VERSION "f33"

NS_ :

BS_:

BU_: C70 VC BMS CHG DASH PBX MCAN OA

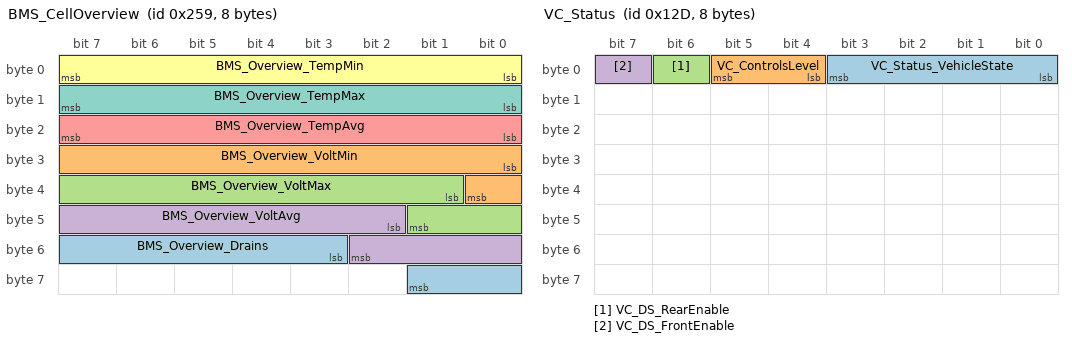
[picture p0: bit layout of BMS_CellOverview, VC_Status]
BO_ 601 BMS_CellOverview: 8 BMS
 SG_ BMS_Overview_Drains : 51|7@1+ (1,0) [0|76] "" Vector__XXX
 SG_ BMS_Overview_VoltMin : 24|9@1+ (0.01,0) [0|5.12] "V"  DASH
 SG_ BMS_Overview_VoltMax : 33|9@1+ (0.01,0) [0|5.12] "V"  DASH
 SG_ BMS_Overview_VoltAvg : 42|9@1+ (0.01,0) [0|5.12] "V" Vector__XXX
 SG_ BMS_Overview_TempAvg : 16|8@1- (1,0) [-128|127] "C" Vector__XXX
 SG_ BMS_Overview_TempMin : 0|8@1- (1,0) [-128|127] "C" Vector__XXX
 SG_ BMS_Overview_TempMax : 8|8@1- (1,0) [-128|127] "C" Vector__XXX

BO_ 301 VC_Status: 8 VC
 SG_ VC_Status_VehicleState : 0|4@1+ (1,0) [0|15] ""  Vector__XXX
 SG_ VC_ControlsLevel : 4|2@1+ (1,0) [0|0] "" Vector__XXX
 SG_ VC_DS_RearEnable : 6|1@1+ (1,0) [0|0] "" Vector__XXX
 SG_ VC_DS_FrontEnable : 7|1@1+ (1,0) [0|0] "" Vector__XXX

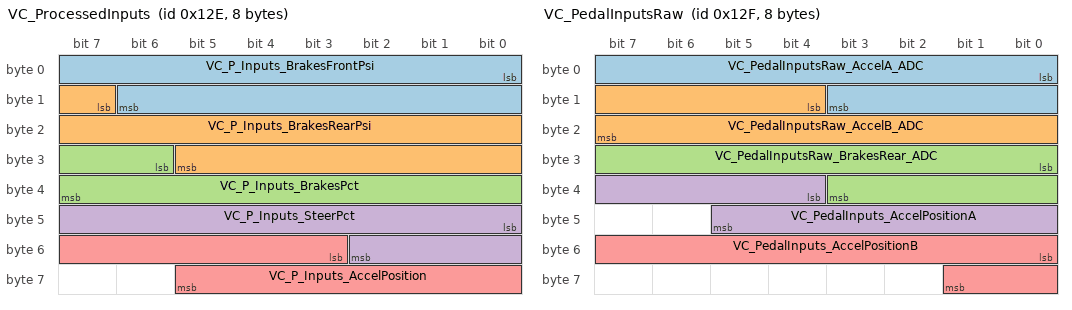
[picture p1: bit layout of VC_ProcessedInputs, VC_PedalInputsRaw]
BO_ 302 VC_ProcessedInputs: 8 VC
 SG_ VC_P_Inputs_BrakesFrontPsi : 0|15@1+ (0.1,0) [0|3000] "psi" Vector__XXX
 SG_ VC_P_Inputs_BrakesRearPsi : 15|15@1+ (0.1,0) [0|3000] "psi" Vector__XXX
 SG_ VC_P_Inputs_BrakesPct : 30|10@1+ (0.1,0) [0|100] "%" Vector__XXX
 SG_ VC_P_Inputs_SteerPct : 40|11@1- (0.1,0) [-100|100] "%" Vector__XXX
 SG_ VC_P_Inputs_AccelPosition : 51|11@1- (0.1,0) [-100|100] "%" Vector__XXX

BO_ 303 VC_PedalInputsRaw: 8 VC
 SG_ VC_PedalInputsRaw_AccelA_ADC : 0|12@1+ (1,0) [0|4095] "" Vector__XXX
 SG_ VC_PedalInputsRaw_AccelB_ADC : 12|12@1+ (1,0) [0|4095] "" Vector__XXX
 SG_ VC_PedalInputsRaw_BrakesRear_ADC : 24|12@1+ (1,0) [0|4095] "" Vector__XXX
 SG_ VC_PedalInputs_AccelPositionA : 36|10@1+ (0.1,0) [0|100] "%" Vector__XXX
 SG_ VC_PedalInputs_AccelPositionB : 48|10@1+ (0.1,0) [0|100] "%" Vector__XXX

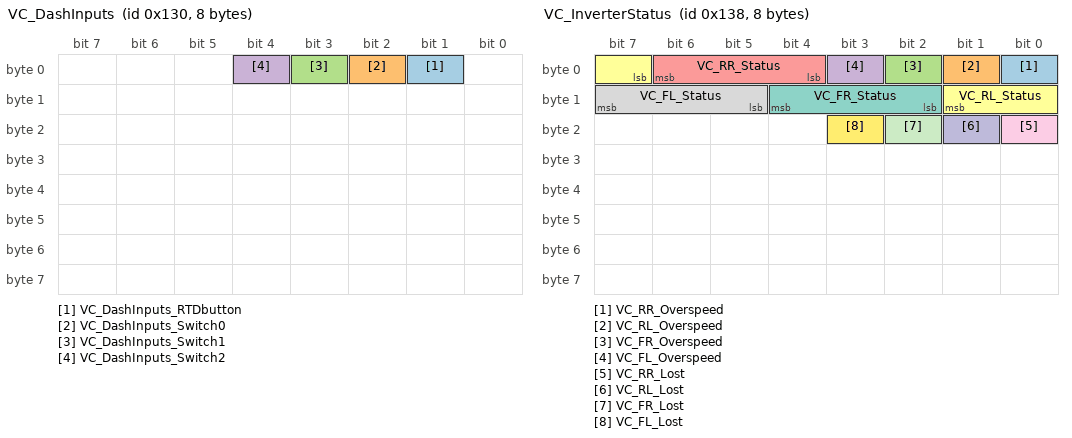
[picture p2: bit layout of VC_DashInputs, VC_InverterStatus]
BO_ 304 VC_DashInputs: 8 VC
 SG_ VC_DashInputs_RTDbutton : 1|1@1+ (1,0) [0|1] "" Vector__XXX
 SG_ VC_DashInputs_Switch0 : 2|1@1+ (1,0) [0|1] "" Vector__XXX
 SG_ VC_DashInputs_Switch1 : 3|1@1+ (1,0) [0|1] "" Vector__XXX
 SG_ VC_DashInputs_Switch2 : 4|1@1+ (1,0) [0|1] "" Vector__XXX

BO_ 311 VC_FaultVector: 8 VC
 SG_ VC_PBX_SHUTDOWN_CONTROL : 0|1@1+ (1,0) [0|1] ""  Vector__XXX
 SG_ VC_ShutdownStatus_BMS_fault : 1|1@1+ (1,0) [0|1] "" Vector__XXX
 SG_ VC_FaultVector_ACCEL_A_IRRA : 2|1@1+ (1,0) [0|1] "" Vector__XXX
 SG_ VC_FaultVector_ACCEL_B_IRRA : 3|1@1+ (1,0) [0|1] "" Vector__XXX
 SG_ VC_FaultVector_APPS_DISAG : 4|1@1+ (1,0) [0|1] "" Vector__XXX
 SG_ VC_FaultVector_APPS_DOUBLE_PEDAL : 5|1@1+ (1,0) [0|1] "" Vector__XXX
 SG_ VC_FaultVector_FSSDB_LOST : 6|1@1+ (1,0) [0|1] "" Vector__XXX
 SG_ VC_FaultVector_FBPS_IRRA : 7|1@1+ (1,0) [0|1] "" Vector__XXX
 SG_ VC_FaultVector_RBPS_IRRA : 8|1@1+ (1,0) [0|1] "" Vector__XXX
 SG_ VC_FaultVector_STEER_IRRA : 9|1@1+ (1,0) [0|1] ""  Vector__XXX
 SG_ VC_FaultVector_RSSDB_LOST : 10|1@1+ (1,0) [0|1] ""  Vector__XXX
 SG_ VC_FaultVector_RR_ERROR : 11|1@1+ (1,0) [0|1] ""  Vector__XXX
 SG_ VC_FaultVector_RL_ERROR : 12|1@1+ (1,0) [0|1] ""  Vector__XXX
 SG_ VC_FaultVector_FR_ERROR : 13|1@1+ (1,0) [0|1] ""  Vector__XXX
 SG_ VC_FaultVector_FL_ERROR : 14|1@1+ (1,0) [0|1] ""  Vector__XXX
 SG_ VC_FaultVector_PC_TIMEOUT : 15|1@1+ (1,0) [0|1] "" Vector__XXX
 SG_ VC_FaultVector_SOFT_DP : 16|1@1+ (1,0) [0|1] "" Vector__XXX
 SG_ VC_FaultVector_VN_NO_LOCK : 17|1@1+ (1,0) [0|1] "" Vector__XXX
 SG_ VC_FaultVector_VN_IRR : 18|1@1+ (1,0) [0|1] "" Vector__XXX
 SG_ VC_FaultVector_RUNAWAY : 19|1@1+ (1,0) [0|1] "" Vector__XXX

BO_ 312 VC_InverterStatus: 8 VC
 SG_ VC_RR_Overspeed : 0|1@1+ (1,0) [0|1] "" Vector__XXX
 SG_ VC_RL_Overspeed : 1|1@1+ (1,0) [0|1] "" Vector__XXX
 SG_ VC_FR_Overspeed : 2|1@1+ (1,0) [0|1] "" Vector__XXX
 SG_ VC_FL_Overspeed : 3|1@1+ (1,0) [0|1] "" Vector__XXX
 SG_ VC_RR_Status : 4|3@1+ (1,0) [0|7] "" Vector__XXX
 SG_ VC_RL_Status : 7|3@1+ (1,0) [0|7] "" Vector__XXX
 SG_ VC_FR_Status : 10|3@1+ (1,0) [0|7] "" Vector__XXX
 SG_ VC_FL_Status : 13|3@1+ (1,0) [0|7] "" Vector__XXX
 SG_ VC_RR_Lost : 16|1@1+ (1,0) [0|1] "" Vector__XXX
 SG_ VC_RL_Lost : 17|1@1+ (1,0) [0|1] "" Vector__XXX
 SG_ VC_FR_Lost : 18|1@1+ (1,0) [0|1] "" Vector__XXX
 SG_ VC_FL_Lost : 19|1@1+ (1,0) [0|1] "" Vector__XXX

BO_ 315 VC_HardFaultIndicator: 8 VC
 SG_ VC_HardFaultIndicator : 0|4@1+ (1,0) [0|15] ""  DASH

BO_ 316 VC_RTDSRequest: 8 VC
 SG_ VC_RequestRTDS : 0|1@1+ (1,0) [0|1] "" Vector__XXX

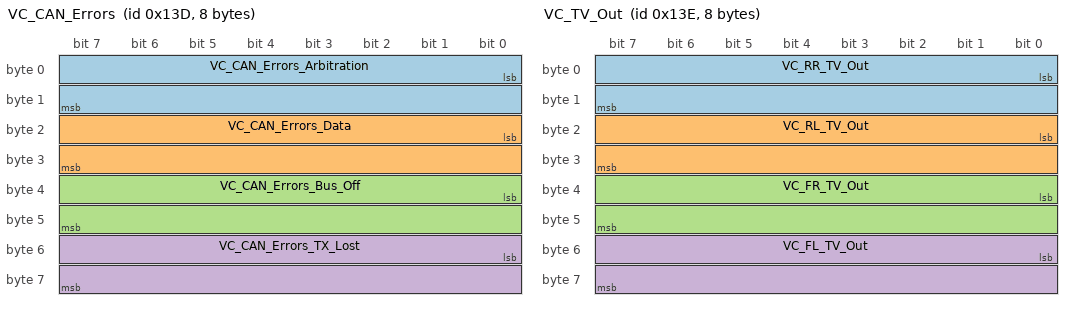
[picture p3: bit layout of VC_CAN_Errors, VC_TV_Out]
BO_ 317 VC_CAN_Errors: 8 VC
 SG_ VC_CAN_Errors_Arbitration : 0|16@1+ (1,0) [0|0] "" Vector__XXX
 SG_ VC_CAN_Errors_Data : 16|16@1+ (1,0) [0|0] "" Vector__XXX
 SG_ VC_CAN_Errors_Bus_Off : 32|16@1+ (1,0) [0|0] "" Vector__XXX
 SG_ VC_CAN_Errors_TX_Lost : 48|16@1+ (1,0) [0|0] "" Vector__XXX

BO_ 318 VC_TV_Out: 8 VC
 SG_ VC_RR_TV_Out: 0|16@1+ (0.1,0) [0|0] "% Mn" Vector__XXX
 SG_ VC_RL_TV_Out: 16|16@1+ (0.1,0) [0|0] "% Mn" Vector__XXX
 SG_ VC_FR_TV_Out: 32|16@1+ (0.1,0) [0|0] "% Mn" Vector__XXX
 SG_ VC_FL_TV_Out: 48|16@1+ (0.1,0) [0|0] "% Mn" Vector__XXX

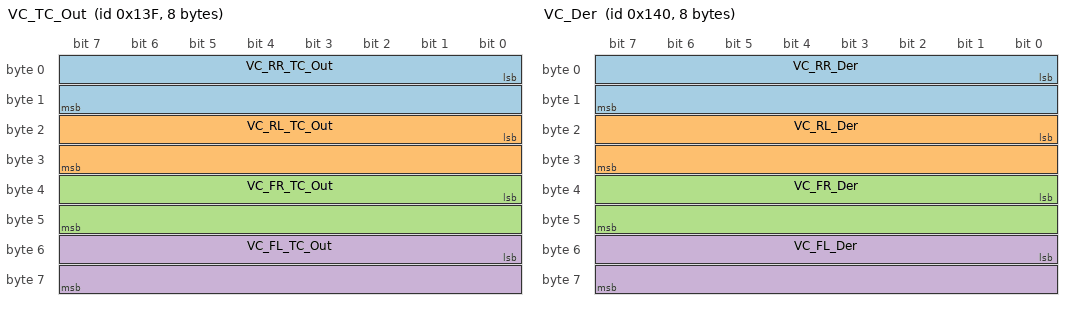
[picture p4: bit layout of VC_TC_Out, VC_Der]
BO_ 319 VC_TC_Out: 8 VC
 SG_ VC_RR_TC_Out: 0|16@1+ (0.1,0) [0|0] "% Mn" Vector__XXX
 SG_ VC_RL_TC_Out: 16|16@1+ (0.1,0) [0|0] "% Mn" Vector__XXX
 SG_ VC_FR_TC_Out: 32|16@1+ (0.1,0) [0|0] "% Mn" Vector__XXX
 SG_ VC_FL_TC_Out: 48|16@1+ (0.1,0) [0|0] "% Mn" Vector__XXX

BO_ 320 VC_Der: 8 VC
 SG_ VC_RR_Der: 0|16@1+ (0.1,0) [0|0] "rpm" Vector__XXX
 SG_ VC_RL_Der: 16|16@1+ (0.1,0) [0|0] "rpm" Vector__XXX
 SG_ VC_FR_Der: 32|16@1+ (0.1,0) [0|0] "rpm" Vector__XXX
 SG_ VC_FL_Der: 48|16@1+ (0.1,0) [0|0] "rpm" Vector__XXX

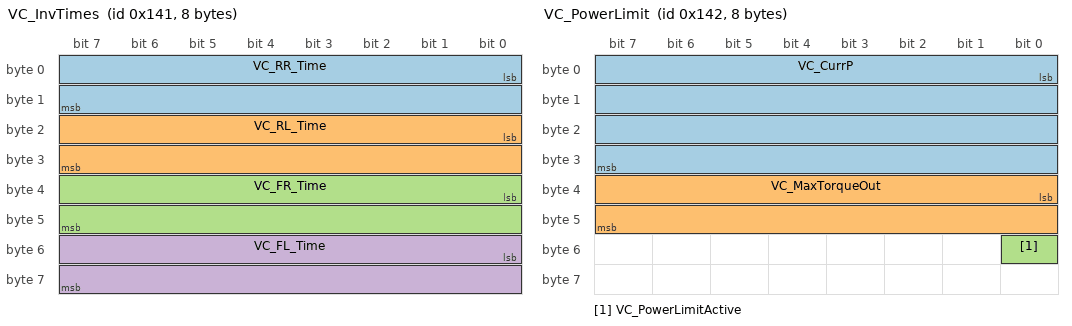
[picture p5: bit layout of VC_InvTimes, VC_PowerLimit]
BO_ 321 VC_InvTimes: 8 VC
 SG_ VC_RR_Time : 0|16@1+ (1,0) [0|65535] "" Vector__XXX
 SG_ VC_RL_Time : 16|16@1+ (1,0) [0|65535] "" Vector__XXX
 SG_ VC_FR_Time : 32|16@1+ (1,0) [0|65535] "" Vector__XXX
 SG_ VC_FL_Time : 48|16@1+ (1,0) [0|65535] "" Vector__XXX

BO_ 322 VC_PowerLimit: 8 VC
 SG_ VC_CurrP : 0|32@1+ (0.01,0) [0|0] "W" Vector__XXX
 SG_ VC_MaxTorqueOut : 32|16@1+ (0.1,0) [0|0] "%Mn" Vector__XXX
 SG_ VC_PowerLimitActive : 48|1@1+ (1,0) [0|1] "" Vector__XXX

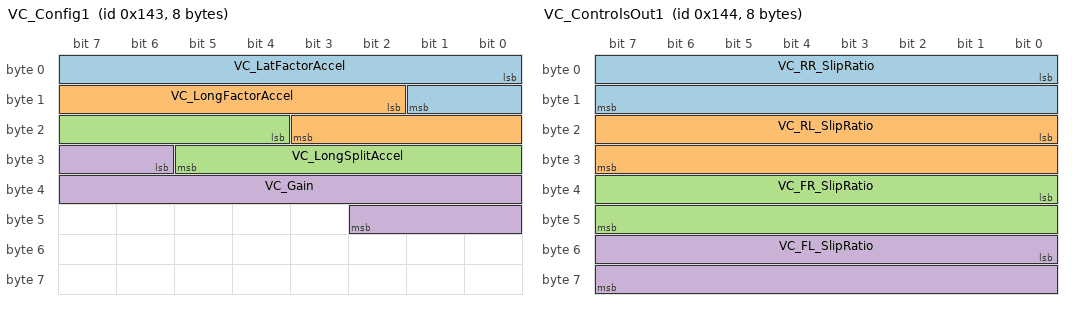
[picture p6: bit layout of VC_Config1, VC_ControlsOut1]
BO_ 323 VC_Config1: 8 VC
 SG_ VC_LatFactorAccel : 0|10@1+ (0.01,0) [0|0] "" Vector__XXX
 SG_ VC_LongFactorAccel : 10|10@1+ (0.01,0) [0|0] "" Vector__XXX
 SG_ VC_LongSplitAccel : 20|10@1+ (0.01,0) [0|0] "" Vector__XXX
 SG_ VC_Gain : 30|13@1+ (0.01,0) [0|0] "" Vector__XXX

BO_ 324 VC_ControlsOut1: 8 VC
 SG_ VC_RR_SlipRatio : 0|16@1+ (0.001,0) [0|0] "" Vector__XXX
 SG_ VC_RL_SlipRatio : 16|16@1+ (0.001,0) [0|0] "" Vector__XXX
 SG_ VC_FR_SlipRatio : 32|16@1+ (0.001,0) [0|0] "" Vector__XXX
 SG_ VC_FL_SlipRatio : 48|16@1+ (0.001,0) [0|0] "" Vector__XXX

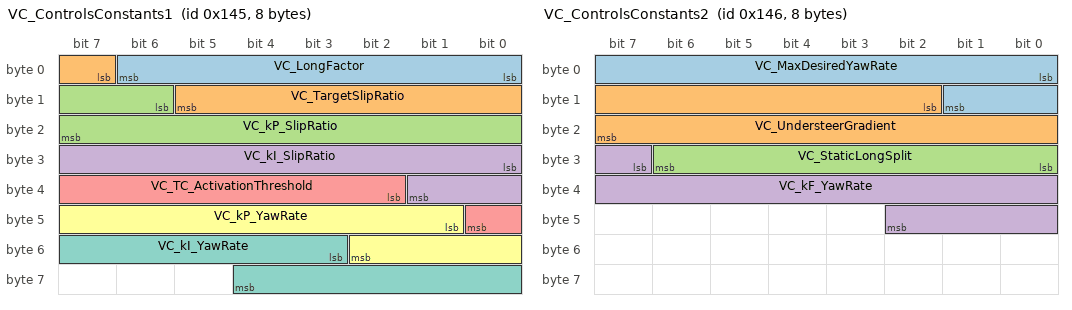
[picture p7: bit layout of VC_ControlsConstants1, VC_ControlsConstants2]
BO_ 325 VC_ControlsConstants1 : 8 VC
 SG_ VC_LongFactor : 0|7@1+ (0.01,0) [0|0] "" Vector__XXX
 SG_ VC_TargetSlipRatio : 7|7@1+ (0.01,0) [0|0] "" Vector__XXX
 SG_ VC_kP_SlipRatio : 14|10@1+ (0.01,0) [0|0] "" Vector__XXX
 SG_ VC_kI_SlipRatio : 24|10@1+ (0.01,0) [0|0] "" Vector__XXX
 SG_ VC_TC_ActivationThreshold : 34|7@1+ (0.01,0) [0|0] "" Vector__XXX
 SG_ VC_kP_YawRate : 41|10@1+ (0.01,0) [0|0] "" Vector__XXX
 SG_ VC_kI_YawRate : 51|10@1+ (0.01,0) [0|0] "" Vector__XXX

BO_ 326 VC_ControlsConstants2 : 8 VC
 SG_ VC_MaxDesiredYawRate : 0|10@1+ (0.01,0) [0|0] "" Vector__XXX
 SG_ VC_UndersteerGradient : 10|14@1+ (0.00001,0) [0|0] "" Vector__XXX
 SG_ VC_StaticLongSplit : 24|7@1+ (0.01,0) [0|0] "" Vector__XXX
 SG_ VC_kF_YawRate : 31|12@1+ (0.01, 0) [0|0] "" Vector__XXX

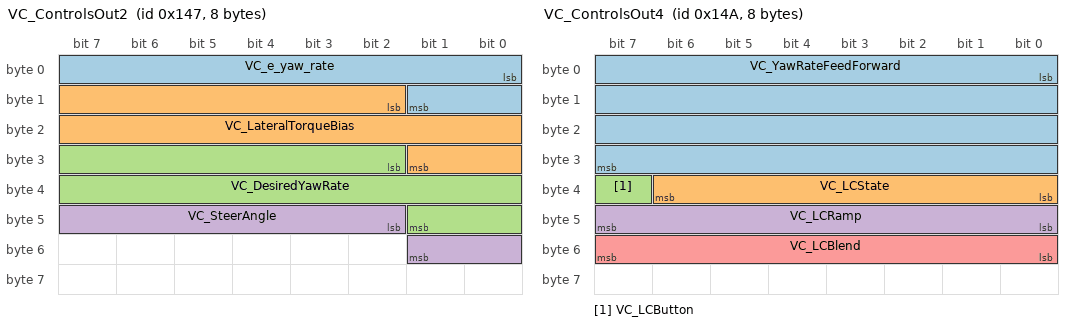
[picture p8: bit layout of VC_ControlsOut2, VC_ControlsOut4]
BO_ 327 VC_ControlsOut2: 8 VC
 SG_ VC_e_yaw_rate : 0|10@1- (0.01,0) [0|0] "rad/s" Vector__XXX
 SG_ VC_LateralTorqueBias : 10|16@1- (0.01,0) [0|0] "Nm" Vector__XXX
 SG_ VC_DesiredYawRate : 26|16@1- (0.001,0) [0|0] "rad/s" Vector__XXX
 SG_ VC_SteerAngle : 42|8@1- (1,0) [0|0] "deg" Vector__XXX

BO_ 328 VC_ControlsDebug: 8 VC
 SG_ VC_debug1 : 0|32@1+ (1,0) [0|0] "" Vector__XXX
 SG_ VC_debug2 : 32|32@1+ (1,0) [0|0] "" Vector__XXX

BO_ 329 VC_ControlsOut3: 8 VC
 SG_ VC_YawRateProportional : 0|32@1+ (1,0) [0|0] "Nm" Vector__XXX
 SG_ VC_YawRateIntegral : 32|32@1+ (1,0) [0|0] "Nm" Vector__XXX

BO_ 330 VC_ControlsOut4: 8 VC
 SG_ VC_YawRateFeedForward : 0|32@1+ (1,0) [0|0] "Nm" Vector__XXX
 SG_ VC_LCState: 32|7@1+ (1,0) [0|0] "" Vector__XXX
 SG_ VC_LCButton: 39|1@1+ (1,0) [0|0] "" Vector__XXX
 SG_ VC_LCRamp: 40|8@1+ (1,0) [0|0] "" Vector__XXX
 SG_ VC_LCBlend: 48|8@1+ (1,0) [0|0] "" Vector__XXX

BO_ 331 VC_CodegenOutRear: 8 VC
 SG_ VC_CodegenRR : 0|32@1- (1,0) [0|0] "Nm" Vector__XXX
 SG_ VC_CodegenRL : 32|32@1- (1,0) [0|0] "Nm" Vector__XXX

BO_ 332 VC_CodegenOutFront: 8 VC
 SG_ VC_CodegenFR : 0|32@1- (1,0) [0|0] "Nm" Vector__XXX
 SG_ VC_CodegenFL : 32|32@1- (1,0) [0|0] "Nm" Vector__XXX

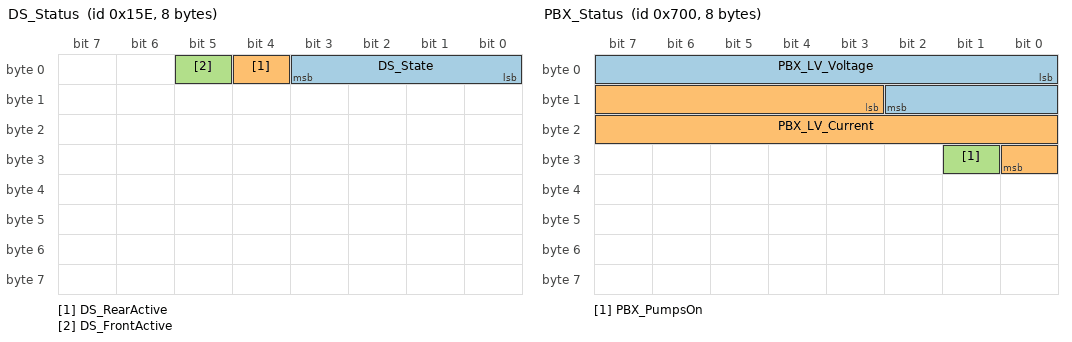
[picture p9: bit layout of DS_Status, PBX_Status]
BO_ 350 DS_Status: 8 LOG
 SG_ DS_State : 0|4@1+ (1,0) [0|0] "" Vector__XXX
 SG_ DS_RearActive : 4|1@1+ (1,0) [0|0] "" Vector__XXX
 SG_ DS_FrontActive : 5|1@1+ (1,0) [0|0] "" Vector__XXX

BO_ 1792 PBX_Status: 8 PBX
 SG_ PBX_LV_Voltage : 0|11@1+ (0.01,0) [0|20] "V" Vector__XXX
 SG_ PBX_LV_Current : 11|14@1+ (0.01,0) [0|100] "A" Vector__XXX
 SG_ PBX_PumpsOn : 25|1@1+ (1,0) [0|1] ""  VC

BO_ 1793 MCAN_C70Control: 1 MCAN
 SG_ MCAN_C70Enable : 0|1@1+ (1,0) [0|1] "" Vector__XXX

BO_ 1794 MCAN_DashControl: 1 MCAN
 SG_ DASH_ActiveScreen : 0|1@1+ (1,0) [0|1] "" Vector__XXX

BO_ 514 BMS_Current_Limit: 8 BMS
 SG_ D1_Max_Discharge_Current : 0|16@1+ (1,0) [0|1000] "A" Vector__XXX
 SG_ D2_Max_Charge_Current : 16|16@1+ (1,0) [0|1000] "A" Vector__XXX

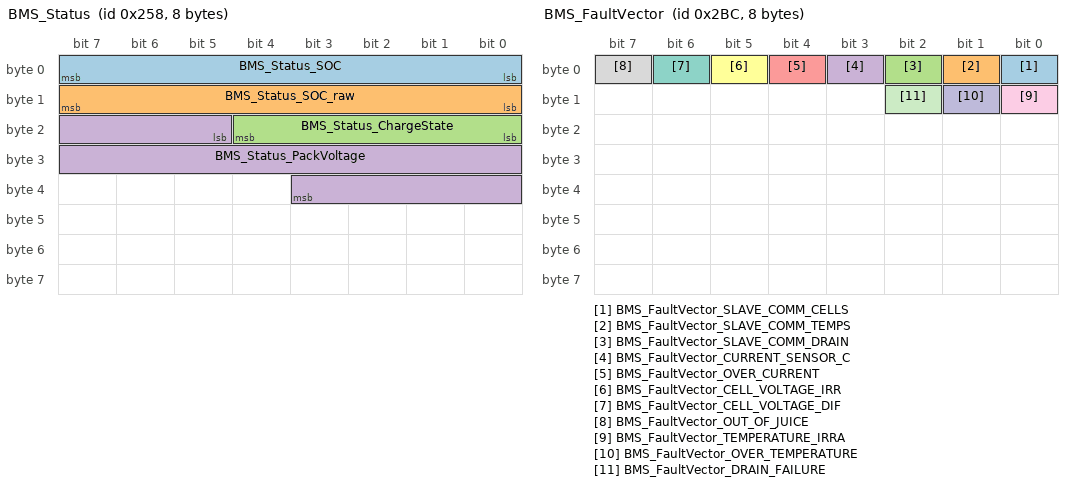
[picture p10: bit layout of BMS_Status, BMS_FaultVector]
BO_ 600 BMS_Status: 8 BMS
 SG_ BMS_Status_SOC : 0|8@1+ (1,0) [0|100] "%"  DASH
 SG_ BMS_Status_SOC_raw : 8|8@1+ (1,0) [0|100] "%" Vector__XXX
 SG_ BMS_Status_ChargeState : 16|5@1+ (1,0) [0|5] "" Vector__XXX
 SG_ BMS_Status_PackVoltage : 21|15@1+ (0.1,0) [0|400] "V"  DASH

BO_ 700 BMS_FaultVector: 8 BMS
 SG_ BMS_FaultVector_SLAVE_COMM_CELLS : 0|1@1+ (1,0) [0|1] ""  DASH
 SG_ BMS_FaultVector_SLAVE_COMM_TEMPS : 1|1@1+ (1,0) [0|1] ""  DASH
 SG_ BMS_FaultVector_SLAVE_COMM_DRAIN : 2|1@1+ (1,0) [0|1] ""  DASH
 SG_ BMS_FaultVector_CURRENT_SENSOR_C : 3|1@1+ (1,0) [0|1] ""  DASH
 SG_ BMS_FaultVector_OVER_CURRENT : 4|1@1+ (1,0) [0|1] ""  DASH
 SG_ BMS_FaultVector_CELL_VOLTAGE_IRR : 5|1@1+ (1,0) [0|1] ""  DASH
 SG_ BMS_FaultVector_CELL_VOLTAGE_DIF : 6|1@1+ (1,0) [0|1] ""  DASH
 SG_ BMS_FaultVector_OUT_OF_JUICE : 7|1@1+ (1,0) [0|1] ""  DASH
 SG_ BMS_FaultVector_TEMPERATURE_IRRA : 8|1@1+ (1,0) [0|1] ""  DASH
 SG_ BMS_FaultVector_OVER_TEMPERATURE : 9|1@1+ (1,0) [0|1] ""  DASH
 SG_ BMS_FaultVector_DRAIN_FAILURE : 10|1@1+ (1,0) [0|1] ""  DASH

BO_ 701 BMS_FaultAlert: 8 BMS
 SG_ BMS_FaultAlert_code M : 0|6@1+ (1,0) [0|63] "" Vector__XXX
 SG_ BMS_FaultAlert_cell_comm_slave_b m0 : 6|8@1+ (1,0) [0|255] "" Vector__XXX
 SG_ BMS_FaultAlert_temp_comm_slave_b m1 : 6|8@1+ (1,0) [0|255] "" Vector__XXX
 SG_ BMS_FaultAlert_drain_comm_slave_ m2 : 6|8@1+ (1,0) [0|255] "" Vector__XXX
 SG_ BMS_FaultAlert_adc_error_code m3 : 6|8@1+ (1,0) [0|255] "" Vector__XXX
 SG_ BMS_FaultAlert_current m4 : 6|32@1+ (0.001,0) [0|2000] "A" Vector__XXX
 SG_ BMS_FaultAlert_irrational_voltag m5 : 6|9@1+ (0.01,0) [0|5.12] "V" Vector__XXX
 SG_ BMS_FaultAlert_voltage_diff m6 : 6|9@1+ (0.01,0) [0|5.12] "V" Vector__XXX
 SG_ BMS_FaultAlert_lowest_cell_volta m7 : 6|9@1+ (0.01,0) [0|5.12] "V" Vector__XXX
 SG_ BMS_FaultAlert_irrational_temper m8 : 6|16@1+ (0.01,0) [-327.68|327.67] "V" Vector__XXX
 SG_ BMS_FaultAlert_over_temperature m9 : 6|16@1+ (0.01,0) [-327.68|327.67] "V" Vector__XXX
 SG_ BMS_FaultAlert_failed_drain_cell m10 : 6|8@1+ (1,0) [0|255] "" Vector__XXX

BO_ 702 BMS_Voltages: 8 BMS
 SG_ BMS_Voltages_mux M : 0|8@1+ (1,0) [0|22] "" Vector__XXX
 SG_ BMS_Voltages_A1 m0 : 8|9@1+ (0.01,0) [0|5.12] "V" Vector__XXX
 SG_ BMS_Voltages_A2 m0 : 17|9@1+ (0.01,0) [0|5.12] "V" Vector__XXX
 SG_ BMS_Voltages_A3 m0 : 26|9@1+ (0.01,0) [0|5.12] "V" Vector__XXX
 SG_ BMS_Voltages_A4 m0 : 35|9@1+ (0.01,0) [0|5.12] "V" Vector__XXX
 SG_ BMS_Voltages_A5 m0 : 44|9@1+ (0.01,0) [0|5.12] "V" Vector__XXX
 SG_ BMS_Voltages_A6 m0 : 53|9@1+ (0.01,0) [0|5.12] "V" Vector__XXX
 SG_ BMS_Voltages_A7 m1 : 8|9@1+ (0.01,0) [0|5.12] "V" Vector__XXX
 SG_ BMS_Voltages_A8 m1 : 17|9@1+ (0.01,0) [0|5.12] "V" Vector__XXX
 SG_ BMS_Voltages_A9 m1 : 26|9@1+ (0.01,0) [0|5.12] "V" Vector__XXX
 SG_ BMS_Voltages_A10 m1 : 35|9@1+ (0.01,0) [0|5.12] "V" Vector__XXX
 SG_ BMS_Voltages_A11 m1 : 44|9@1+ (0.01,0) [0|5.12] "V" Vector__XXX
 SG_ BMS_Voltages_A12 m1 : 53|9@1+ (0.01,0) [0|5.12] "V" Vector__XXX
 SG_ BMS_Voltages_A13 m2 : 8|9@1+ (0.01,0) [0|5.12] "V" Vector__XXX
 SG_ BMS_Voltages_A14 m2 : 17|9@1+ (0.01,0) [0|5.12] "V" Vector__XXX
 SG_ BMS_Voltages_A15 m2 : 26|9@1+ (0.01,0) [0|5.12] "V" Vector__XXX
 SG_ BMS_Voltages_A16 m2 : 35|9@1+ (0.01,0) [0|5.12] "V" Vector__XXX
 SG_ BMS_Voltages_A17 m2 : 44|9@1+ (0.01,0) [0|5.12] "V" Vector__XXX
 SG_ BMS_Voltages_B1 m2 : 53|9@1+ (0.01,0) [0|5.12] "V" Vector__XXX
 SG_ BMS_Voltages_B2 m3 : 8|9@1+ (0.01,0) [0|5.12] "V" Vector__XXX
 SG_ BMS_Voltages_B3 m3 : 17|9@1+ (0.01,0) [0|5.12] "V" Vector__XXX
 SG_ BMS_Voltages_B4 m3 : 26|9@1+ (0.01,0) [0|5.12] "V" Vector__XXX
 SG_ BMS_Voltages_B5 m3 : 35|9@1+ (0.01,0) [0|5.12] "V" Vector__XXX
 SG_ BMS_Voltages_B6 m3 : 44|9@1+ (0.01,0) [0|5.12] "V" Vector__XXX
 SG_ BMS_Voltages_B7 m3 : 53|9@1+ (0.01,0) [0|5.12] "V" Vector__XXX
 SG_ BMS_Voltages_B8 m4 : 8|9@1+ (0.01,0) [0|5.12] "V" Vector__XXX
 SG_ BMS_Voltages_B9 m4 : 17|9@1+ (0.01,0) [0|5.12] "V" Vector__XXX
 SG_ BMS_Voltages_B10 m4 : 26|9@1+ (0.01,0) [0|5.12] "V" Vector__XXX
 SG_ BMS_Voltages_B11 m4 : 35|9@1+ (0.01,0) [0|5.12] "V" Vector__XXX
 SG_ BMS_Voltages_B12 m4 : 44|9@1+ (0.01,0) [0|5.12] "V" Vector__XXX
 SG_ BMS_Voltages_B13 m4 : 53|9@1+ (0.01,0) [0|5.12] "V" Vector__XXX
 SG_ BMS_Voltages_B14 m5 : 8|9@1+ (0.01,0) [0|5.12] "V" Vector__XXX
 SG_ BMS_Voltages_B15 m5 : 17|9@1+ (0.01,0) [0|5.12] "V" Vector__XXX
 SG_ BMS_Voltages_B16 m5 : 26|9@1+ (0.01,0) [0|5.12] "V" Vector__XXX
 SG_ BMS_Voltages_B17 m5 : 35|9@1+ (0.01,0) [0|5.12] "V" Vector__XXX
 SG_ BMS_Voltages_C1 m5 : 44|9@1+ (0.01,0) [0|5.12] "V" Vector__XXX
 SG_ BMS_Voltages_C2 m5 : 53|9@1+ (0.01,0) [0|5.12] "V" Vector__XXX
 SG_ BMS_Voltages_C3 m6 : 8|9@1+ (0.01,0) [0|5.12] "V" Vector__XXX
 SG_ BMS_Voltages_C4 m6 : 17|9@1+ (0.01,0) [0|5.12] "V" Vector__XXX
 SG_ BMS_Voltages_C5 m6 : 26|9@1+ (0.01,0) [0|5.12] "V" Vector__XXX
 SG_ BMS_Voltages_C6 m6 : 35|9@1+ (0.01,0) [0|5.12] "V" Vector__XXX
 SG_ BMS_Voltages_C7 m6 : 44|9@1+ (0.01,0) [0|5.12] "V" Vector__XXX
 SG_ BMS_Voltages_C8 m6 : 53|9@1+ (0.01,0) [0|5.12] "V" Vector__XXX
 SG_ BMS_Voltages_C9 m7 : 8|9@1+ (0.01,0) [0|5.12] "V" Vector__XXX
 SG_ BMS_Voltages_C10 m7 : 17|9@1+ (0.01,0) [0|5.12] "V" Vector__XXX
 SG_ BMS_Voltages_C11 m7 : 26|9@1+ (0.01,0) [0|5.12] "V" Vector__XXX
 SG_ BMS_Voltages_C12 m7 : 35|9@1+ (0.01,0) [0|5.12] "V" Vector__XXX
 SG_ BMS_Voltages_C13 m7 : 44|9@1+ (0.01,0) [0|5.12] "V" Vector__XXX
 SG_ BMS_Voltages_C14 m7 : 53|9@1+ (0.01,0) [0|5.12] "V" Vector__XXX
 SG_ BMS_Voltages_C15 m8 : 8|9@1+ (0.01,0) [0|5.12] "V" Vector__XXX
 SG_ BMS_Voltages_C16 m8 : 17|9@1+ (0.01,0) [0|5.12] "V" Vector__XXX
 SG_ BMS_Voltages_C17 m8 : 26|9@1+ (0.01,0) [0|5.12] "V" Vector__XXX
 SG_ BMS_Voltages_D1 m8 : 35|9@1+ (0.01,0) [0|5.12] "V" Vector__XXX
 SG_ BMS_Voltages_D2 m8 : 44|9@1+ (0.01,0) [0|5.12] "V" Vector__XXX
 SG_ BMS_Voltages_D3 m8 : 53|9@1+ (0.01,0) [0|5.12] "V" Vector__XXX
 SG_ BMS_Voltages_D4 m9 : 8|9@1+ (0.01,0) [0|5.12] "V" Vector__XXX
 SG_ BMS_Voltages_D5 m9 : 17|9@1+ (0.01,0) [0|5.12] "V" Vector__XXX
 SG_ BMS_Voltages_D6 m9 : 26|9@1+ (0.01,0) [0|5.12] "V" Vector__XXX
 SG_ BMS_Voltages_D7 m9 : 35|9@1+ (0.01,0) [0|5.12] "V" Vector__XXX
 SG_ BMS_Voltages_D8 m9 : 44|9@1+ (0.01,0) [0|5.12] "V" Vector__XXX
 SG_ BMS_Voltages_D9 m9 : 53|9@1+ (0.01,0) [0|5.12] "V" Vector__XXX
 SG_ BMS_Voltages_D10 m10 : 8|9@1+ (0.01,0) [0|5.12] "V" Vector__XXX
 SG_ BMS_Voltages_D11 m10 : 17|9@1+ (0.01,0) [0|5.12] "V" Vector__XXX
 SG_ BMS_Voltages_D12 m10 : 26|9@1+ (0.01,0) [0|5.12] "V" Vector__XXX
 SG_ BMS_Voltages_D13 m10 : 35|9@1+ (0.01,0) [0|5.12] "V" Vector__XXX
 SG_ BMS_Voltages_D14 m10 : 44|9@1+ (0.01,0) [0|5.12] "V" Vector__XXX
 SG_ BMS_Voltages_D15 m10 : 53|9@1+ (0.01,0) [0|5.12] "V" Vector__XXX
 SG_ BMS_Voltages_D16 m11 : 8|9@1+ (0.01,0) [0|5.12] "V" Vector__XXX
 SG_ BMS_Voltages_D17 m11 : 17|9@1+ (0.01,0) [0|5.12] "V" Vector__XXX
 SG_ BMS_Voltages_E1 m11 : 26|9@1+ (0.01,0) [0|5.12] "V" Vector__XXX
 SG_ BMS_Voltages_E2 m11 : 35|9@1+ (0.01,0) [0|5.12] "V" Vector__XXX
 SG_ BMS_Voltages_E3 m11 : 44|9@1+ (0.01,0) [0|5.12] "V" Vector__XXX
 SG_ BMS_Voltages_E4 m11 : 53|9@1+ (0.01,0) [0|5.12] "V" Vector__XXX
 SG_ BMS_Voltages_E5 m12 : 8|9@1+ (0.01,0) [0|5.12] "V" Vector__XXX
 SG_ BMS_Voltages_E6 m12 : 17|9@1+ (0.01,0) [0|5.12] "V" Vector__XXX
 SG_ BMS_Voltages_E7 m12 : 26|9@1+ (0.01,0) [0|5.12] "V" Vector__XXX
 SG_ BMS_Voltages_E8 m12 : 35|9@1+ (0.01,0) [0|5.12] "V" Vector__XXX
 SG_ BMS_Voltages_E9 m12 : 44|9@1+ (0.01,0) [0|5.12] "V" Vector__XXX
 SG_ BMS_Voltages_E10 m12 : 53|9@1+ (0.01,0) [0|5.12] "V" Vector__XXX
 SG_ BMS_Voltages_E11 m13 : 8|9@1+ (0.01,0) [0|5.12] "V" Vector__XXX
 SG_ BMS_Voltages_E12 m13 : 17|9@1+ (0.01,0) [0|5.12] "V" Vector__XXX
 SG_ BMS_Voltages_E13 m13 : 26|9@1+ (0.01,0) [0|5.12] "V" Vector__XXX
 SG_ BMS_Voltages_E14 m13 : 35|9@1+ (0.01,0) [0|5.12] "V" Vector__XXX
 SG_ BMS_Voltages_E15 m13 : 44|9@1+ (0.01,0) [0|5.12] "V" Vector__XXX
 SG_ BMS_Voltages_E16 m13 : 53|9@1+ (0.01,0) [0|5.12] "V" Vector__XXX
 SG_ BMS_Voltages_E17 m14 : 8|9@1+ (0.01,0) [0|5.12] "V" Vector__XXX
 SG_ BMS_Voltages_F1 m14 : 17|9@1+ (0.01,0) [0|5.12] "V" Vector__XXX
 SG_ BMS_Voltages_F2 m14 : 26|9@1+ (0.01,0) [0|5.12] "V" Vector__XXX
 SG_ BMS_Voltages_F3 m14 : 35|9@1+ (0.01,0) [0|5.12] "V" Vector__XXX
 SG_ BMS_Voltages_F4 m14 : 44|9@1+ (0.01,0) [0|5.12] "V" Vector__XXX
 SG_ BMS_Voltages_F5 m14 : 53|9@1+ (0.01,0) [0|5.12] "V" Vector__XXX
 SG_ BMS_Voltages_F6 m15 : 8|9@1+ (0.01,0) [0|5.12] "V" Vector__XXX
 SG_ BMS_Voltages_F7 m15 : 17|9@1+ (0.01,0) [0|5.12] "V" Vector__XXX
 SG_ BMS_Voltages_F8 m15 : 26|9@1+ (0.01,0) [0|5.12] "V" Vector__XXX
 SG_ BMS_Voltages_F9 m15 : 35|9@1+ (0.01,0) [0|5.12] "V" Vector__XXX
 SG_ BMS_Voltages_F10 m15 : 44|9@1+ (0.01,0) [0|5.12] "V" Vector__XXX
 SG_ BMS_Voltages_F11 m15 : 53|9@1+ (0.01,0) [0|5.12] "V" Vector__XXX
 SG_ BMS_Voltages_F12 m16 : 8|9@1+ (0.01,0) [0|5.12] "V" Vector__XXX
 SG_ BMS_Voltages_F13 m16 : 17|9@1+ (0.01,0) [0|5.12] "V" Vector__XXX
 SG_ BMS_Voltages_F14 m16 : 26|9@1+ (0.01,0) [0|5.12] "V" Vector__XXX
 SG_ BMS_Voltages_F15 m16 : 35|9@1+ (0.01,0) [0|5.12] "V" Vector__XXX
 SG_ BMS_Voltages_F16 m16 : 44|9@1+ (0.01,0) [0|5.12] "V" Vector__XXX
 SG_ BMS_Voltages_F17 m16 : 53|9@1+ (0.01,0) [0|5.12] "V" Vector__XXX
 SG_ BMS_Voltages_G1 m17 : 8|9@1+ (0.01,0) [0|5.12] "V" Vector__XXX
 SG_ BMS_Voltages_G2 m17 : 17|9@1+ (0.01,0) [0|5.12] "V" Vector__XXX
 SG_ BMS_Voltages_G3 m17 : 26|9@1+ (0.01,0) [0|5.12] "V" Vector__XXX
 SG_ BMS_Voltages_G4 m17 : 35|9@1+ (0.01,0) [0|5.12] "V" Vector__XXX
 SG_ BMS_Voltages_G5 m17 : 44|9@1+ (0.01,0) [0|5.12] "V" Vector__XXX
 SG_ BMS_Voltages_G6 m17 : 53|9@1+ (0.01,0) [0|5.12] "V" Vector__XXX
 SG_ BMS_Voltages_G7 m18 : 8|9@1+ (0.01,0) [0|5.12] "V" Vector__XXX
 SG_ BMS_Voltages_G8 m18 : 17|9@1+ (0.01,0) [0|5.12] "V" Vector__XXX
 SG_ BMS_Voltages_G9 m18 : 26|9@1+ (0.01,0) [0|5.12] "V" Vector__XXX
 SG_ BMS_Voltages_G10 m18 : 35|9@1+ (0.01,0) [0|5.12] "V" Vector__XXX
 SG_ BMS_Voltages_G11 m18 : 44|9@1+ (0.01,0) [0|5.12] "V" Vector__XXX
 SG_ BMS_Voltages_G12 m18 : 53|9@1+ (0.01,0) [0|5.12] "V" Vector__XXX
 SG_ BMS_Voltages_G13 m19 : 8|9@1+ (0.01,0) [0|5.12] "V" Vector__XXX
 SG_ BMS_Voltages_G14 m19 : 17|9@1+ (0.01,0) [0|5.12] "V" Vector__XXX
 SG_ BMS_Voltages_G15 m19 : 26|9@1+ (0.01,0) [0|5.12] "V" Vector__XXX
 SG_ BMS_Voltages_G16 m19 : 35|9@1+ (0.01,0) [0|5.12] "V" Vector__XXX
 SG_ BMS_Voltages_G17 m19 : 44|9@1+ (0.01,0) [0|5.12] "V" Vector__XXX
 SG_ BMS_Voltages_H1 m19 : 53|9@1+ (0.01,0) [0|5.12] "V" Vector__XXX
 SG_ BMS_Voltages_H2 m20 : 8|9@1+ (0.01,0) [0|5.12] "V" Vector__XXX
 SG_ BMS_Voltages_H3 m20 : 17|9@1+ (0.01,0) [0|5.12] "V" Vector__XXX
 SG_ BMS_Voltages_H4 m20 : 26|9@1+ (0.01,0) [0|5.12] "V" Vector__XXX
 SG_ BMS_Voltages_H5 m20 : 35|9@1+ (0.01,0) [0|5.12] "V" Vector__XXX
 SG_ BMS_Voltages_H6 m20 : 44|9@1+ (0.01,0) [0|5.12] "V" Vector__XXX
 SG_ BMS_Voltages_H7 m20 : 53|9@1+ (0.01,0) [0|5.12] "V" Vector__XXX
 SG_ BMS_Voltages_H8 m21 : 8|9@1+ (0.01,0) [0|5.12] "V" Vector__XXX
 SG_ BMS_Voltages_H9 m21 : 17|9@1+ (0.01,0) [0|5.12] "V" Vector__XXX
 SG_ BMS_Voltages_H10 m21 : 26|9@1+ (0.01,0) [0|5.12] "V" Vector__XXX
 SG_ BMS_Voltages_H11 m21 : 35|9@1+ (0.01,0) [0|5.12] "V" Vector__XXX
 SG_ BMS_Voltages_H12 m21 : 44|9@1+ (0.01,0) [0|5.12] "V" Vector__XXX
 SG_ BMS_Voltages_H13 m21 : 53|9@1+ (0.01,0) [0|5.12] "V" Vector__XXX
 SG_ BMS_Voltages_H14 m22 : 8|9@1+ (0.01,0) [0|5.12] "V" Vector__XXX
 SG_ BMS_Voltages_H15 m22 : 17|9@1+ (0.01,0) [0|5.12] "V" Vector__XXX
 SG_ BMS_Voltages_H16 m22 : 26|9@1+ (0.01,0) [0|5.12] "V" Vector__XXX
 SG_ BMS_Voltages_H17 m22 : 35|9@1+ (0.01,0) [0|5.12] "V" Vector__XXX

BO_ 703 BMS_ThermistorVoltages: 8 BMS
 SG_ BMS_ThermistorVoltages_mux M : 0|3@1+ (1,0) [0|5] "" Vector__XXX
 SG_ BMS_ThermistorVoltages_A1 m0 : 3|9@1+ (0.01,0) [0|5.12] "V" Vector__XXX
 SG_ BMS_ThermistorVoltages_A2 m0 : 12|9@1+ (0.01,0) [0|5.12] "V" Vector__XXX
 SG_ BMS_ThermistorVoltages_A3 m0 : 21|9@1+ (0.01,0) [0|5.12] "V" Vector__XXX
 SG_ BMS_ThermistorVoltages_A4 m0 : 30|9@1+ (0.01,0) [0|5.12] "V" Vector__XXX
 SG_ BMS_ThermistorVoltages_A5 m0 : 39|9@1+ (0.01,0) [0|5.12] "V" Vector__XXX
 SG_ BMS_ThermistorVoltages_A6 m0 : 48|9@1+ (0.01,0) [0|5.12] "V" Vector__XXX
 SG_ BMS_ThermistorVoltages_B1 m1 : 3|9@1+ (0.01,0) [0|5.12] "V" Vector__XXX
 SG_ BMS_ThermistorVoltages_B2 m1 : 12|9@1+ (0.01,0) [0|5.12] "V" Vector__XXX
 SG_ BMS_ThermistorVoltages_B3 m1 : 21|9@1+ (0.01,0) [0|5.12] "V" Vector__XXX
 SG_ BMS_ThermistorVoltages_B4 m1 : 30|9@1+ (0.01,0) [0|5.12] "V" Vector__XXX
 SG_ BMS_ThermistorVoltages_B5 m1 : 39|9@1+ (0.01,0) [0|5.12] "V" Vector__XXX
 SG_ BMS_ThermistorVoltages_B6 m1 : 48|9@1+ (0.01,0) [0|5.12] "V" Vector__XXX
 SG_ BMS_ThermistorVoltages_C1 m2 : 3|9@1+ (0.01,0) [0|5.12] "V" Vector__XXX
 SG_ BMS_ThermistorVoltages_C2 m2 : 12|9@1+ (0.01,0) [0|5.12] "V" Vector__XXX
 SG_ BMS_ThermistorVoltages_C3 m2 : 21|9@1+ (0.01,0) [0|5.12] "V" Vector__XXX
 SG_ BMS_ThermistorVoltages_C4 m2 : 30|9@1+ (0.01,0) [0|5.12] "V" Vector__XXX
 SG_ BMS_ThermistorVoltages_C5 m2 : 39|9@1+ (0.01,0) [0|5.12] "V" Vector__XXX
 SG_ BMS_ThermistorVoltages_C6 m2 : 48|9@1+ (0.01,0) [0|5.12] "V" Vector__XXX
 SG_ BMS_ThermistorVoltages_D1 m3 : 3|9@1+ (0.01,0) [0|5.12] "V" Vector__XXX
 SG_ BMS_ThermistorVoltages_D2 m3 : 12|9@1+ (0.01,0) [0|5.12] "V" Vector__XXX
 SG_ BMS_ThermistorVoltages_D3 m3 : 21|9@1+ (0.01,0) [0|5.12] "V" Vector__XXX
 SG_ BMS_ThermistorVoltages_D4 m3 : 30|9@1+ (0.01,0) [0|5.12] "V" Vector__XXX
 SG_ BMS_ThermistorVoltages_D5 m3 : 39|9@1+ (0.01,0) [0|5.12] "V" Vector__XXX
 SG_ BMS_ThermistorVoltages_D6 m3 : 48|9@1+ (0.01,0) [0|5.12] "V" Vector__XXX
 SG_ BMS_ThermistorVoltages_E1 m4 : 3|9@1+ (0.01,0) [0|5.12] "V" Vector__XXX
 SG_ BMS_ThermistorVoltages_E2 m4 : 12|9@1+ (0.01,0) [0|5.12] "V" Vector__XXX
 SG_ BMS_ThermistorVoltages_E3 m4 : 21|9@1+ (0.01,0) [0|5.12] "V" Vector__XXX
 SG_ BMS_ThermistorVoltages_E4 m4 : 30|9@1+ (0.01,0) [0|5.12] "V" Vector__XXX
 SG_ BMS_ThermistorVoltages_E5 m4 : 39|9@1+ (0.01,0) [0|5.12] "V" Vector__XXX
 SG_ BMS_ThermistorVoltages_E6 m4 : 48|9@1+ (0.01,0) [0|5.12] "V" Vector__XXX
 SG_ BMS_ThermistorVoltages_F1 m5 : 3|9@1+ (0.01,0) [0|5.12] "V" Vector__XXX
 SG_ BMS_ThermistorVoltages_F2 m5 : 12|9@1+ (0.01,0) [0|5.12] "V" Vector__XXX
 SG_ BMS_ThermistorVoltages_F3 m5 : 21|9@1+ (0.01,0) [0|5.12] "V" Vector__XXX
 SG_ BMS_ThermistorVoltages_F4 m5 : 30|9@1+ (0.01,0) [0|5.12] "V" Vector__XXX
 SG_ BMS_ThermistorVoltages_F5 m5 : 39|9@1+ (0.01,0) [0|5.12] "V" Vector__XXX
 SG_ BMS_ThermistorVoltages_F6 m5 : 48|9@1+ (0.01,0) [0|5.12] "V" Vector__XXX
 SG_ BMS_ThermistorVoltages_G1 m6 : 3|9@1+ (0.01,0) [0|5.12] "V" Vector__XXX
 SG_ BMS_ThermistorVoltages_G2 m6 : 12|9@1+ (0.01,0) [0|5.12] "V" Vector__XXX
 SG_ BMS_ThermistorVoltages_G3 m6 : 21|9@1+ (0.01,0) [0|5.12] "V" Vector__XXX
 SG_ BMS_ThermistorVoltages_G4 m6 : 30|9@1+ (0.01,0) [0|5.12] "V" Vector__XXX
 SG_ BMS_ThermistorVoltages_G5 m6 : 39|9@1+ (0.01,0) [0|5.12] "V" Vector__XXX
 SG_ BMS_ThermistorVoltages_G6 m6 : 48|9@1+ (0.01,0) [0|5.12] "V" Vector__XXX
 SG_ BMS_ThermistorVoltages_H1 m7 : 3|9@1+ (0.01,0) [0|5.12] "V" Vector__XXX
 SG_ BMS_ThermistorVoltages_H2 m7 : 12|9@1+ (0.01,0) [0|5.12] "V" Vector__XXX
 SG_ BMS_ThermistorVoltages_H3 m7 : 21|9@1+ (0.01,0) [0|5.12] "V" Vector__XXX
 SG_ BMS_ThermistorVoltages_H4 m7 : 30|9@1+ (0.01,0) [0|5.12] "V" Vector__XXX
 SG_ BMS_ThermistorVoltages_H5 m7 : 39|9@1+ (0.01,0) [0|5.12] "V" Vector__XXX
 SG_ BMS_ThermistorVoltages_H6 m7 : 48|9@1+ (0.01,0) [0|5.12] "V" Vector__XXX

BO_ 704 BMS_Temperatures: 8 BMS
 SG_ BMS_Temperatures_mux M : 0|3@1+ (1,0) [0|7] "" Vector__XXX
 SG_ BMS_Temperatures_A1 m0 : 3|10@1+ (0.1,0) [0|102.3] "C" Vector__XXX
 SG_ BMS_Temperatures_A2 m0 : 13|10@1+ (0.1,0) [0|102.3] "C" Vector__XXX
 SG_ BMS_Temperatures_A3 m0 : 23|10@1+ (0.1,0) [0|102.3] "C" Vector__XXX
 SG_ BMS_Temperatures_A4 m0 : 33|10@1+ (0.1,0) [0|102.3] "C" Vector__XXX
 SG_ BMS_Temperatures_A5 m0 : 43|10@1+ (0.1,0) [0|102.3] "C" Vector__XXX
 SG_ BMS_Temperatures_A6 m0 : 53|10@1+ (0.1,0) [0|102.3] "C" Vector__XXX
 SG_ BMS_Temperatures_B1 m1 : 3|10@1+ (0.1,0) [0|102.3] "C" Vector__XXX
 SG_ BMS_Temperatures_B2 m1 : 13|10@1+ (0.1,0) [0|102.3] "C" Vector__XXX
 SG_ BMS_Temperatures_B3 m1 : 23|10@1+ (0.1,0) [0|102.3] "C" Vector__XXX
 SG_ BMS_Temperatures_B4 m1 : 33|10@1+ (0.1,0) [0|102.3] "C" Vector__XXX
 SG_ BMS_Temperatures_B5 m1 : 43|10@1+ (0.1,0) [0|102.3] "C" Vector__XXX
 SG_ BMS_Temperatures_B6 m1 : 53|10@1+ (0.1,0) [0|102.3] "C" Vector__XXX
 SG_ BMS_Temperatures_C1 m2 : 3|10@1+ (0.1,0) [0|102.3] "C" Vector__XXX
 SG_ BMS_Temperatures_C2 m2 : 13|10@1+ (0.1,0) [0|102.3] "C" Vector__XXX
 SG_ BMS_Temperatures_C3 m2 : 23|10@1+ (0.1,0) [0|102.3] "C" Vector__XXX
 SG_ BMS_Temperatures_C4 m2 : 33|10@1+ (0.1,0) [0|102.3] "C" Vector__XXX
 SG_ BMS_Temperatures_C5 m2 : 43|10@1+ (0.1,0) [0|102.3] "C" Vector__XXX
 SG_ BMS_Temperatures_C6 m2 : 53|10@1+ (0.1,0) [0|102.3] "C" Vector__XXX
 SG_ BMS_Temperatures_D1 m3 : 3|10@1+ (0.1,0) [0|102.3] "C" Vector__XXX
 SG_ BMS_Temperatures_D2 m3 : 13|10@1+ (0.1,0) [0|102.3] "C" Vector__XXX
 SG_ BMS_Temperatures_D3 m3 : 23|10@1+ (0.1,0) [0|102.3] "C" Vector__XXX
 SG_ BMS_Temperatures_D4 m3 : 33|10@1+ (0.1,0) [0|102.3] "C" Vector__XXX
 SG_ BMS_Temperatures_D5 m3 : 43|10@1+ (0.1,0) [0|102.3] "C" Vector__XXX
 SG_ BMS_Temperatures_D6 m3 : 53|10@1+ (0.1,0) [0|102.3] "C" Vector__XXX
 SG_ BMS_Temperatures_E1 m4 : 3|10@1+ (0.1,0) [0|102.3] "C" Vector__XXX
 SG_ BMS_Temperatures_E2 m4 : 13|10@1+ (0.1,0) [0|102.3] "C" Vector__XXX
 SG_ BMS_Temperatures_E3 m4 : 23|10@1+ (0.1,0) [0|102.3] "C" Vector__XXX
 SG_ BMS_Temperatures_E4 m4 : 33|10@1+ (0.1,0) [0|102.3] "C" Vector__XXX
 SG_ BMS_Temperatures_E5 m4 : 43|10@1+ (0.1,0) [0|102.3] "C" Vector__XXX
 SG_ BMS_Temperatures_E6 m4 : 53|10@1+ (0.1,0) [0|102.3] "C" Vector__XXX
 SG_ BMS_Temperatures_F1 m5 : 3|10@1+ (0.1,0) [0|102.3] "C" Vector__XXX
 SG_ BMS_Temperatures_F2 m5 : 13|10@1+ (0.1,0) [0|102.3] "C" Vector__XXX
 SG_ BMS_Temperatures_F3 m5 : 23|10@1+ (0.1,0) [0|102.3] "C" Vector__XXX
 SG_ BMS_Temperatures_F4 m5 : 33|10@1+ (0.1,0) [0|102.3] "C" Vector__XXX
 SG_ BMS_Temperatures_F5 m5 : 43|10@1+ (0.1,0) [0|102.3] "C" Vector__XXX
 SG_ BMS_Temperatures_F6 m5 : 53|10@1+ (0.1,0) [0|102.3] "C" Vector__XXX
 SG_ BMS_Temperatures_G1 m6 : 3|10@1+ (0.1,0) [0|102.3] "C" Vector__XXX
 SG_ BMS_Temperatures_G2 m6 : 13|10@1+ (0.1,0) [0|102.3] "C" Vector__XXX
 SG_ BMS_Temperatures_G3 m6 : 23|10@1+ (0.1,0) [0|102.3] "C" Vector__XXX
 SG_ BMS_Temperatures_G4 m6 : 33|10@1+ (0.1,0) [0|102.3] "C" Vector__XXX
 SG_ BMS_Temperatures_G5 m6 : 43|10@1+ (0.1,0) [0|102.3] "C" Vector__XXX
 SG_ BMS_Temperatures_G6 m6 : 53|10@1+ (0.1,0) [0|102.3] "C" Vector__XXX
 SG_ BMS_Temperatures_H1 m7 : 3|10@1+ (0.1,0) [0|102.3] "C" Vector__XXX
 SG_ BMS_Temperatures_H2 m7 : 13|10@1+ (0.1,0) [0|102.3] "C" Vector__XXX
 SG_ BMS_Temperatures_H3 m7 : 23|10@1+ (0.1,0) [0|102.3] "C" Vector__XXX
 SG_ BMS_Temperatures_H4 m7 : 33|10@1+ (0.1,0) [0|102.3] "C" Vector__XXX
 SG_ BMS_Temperatures_H5 m7 : 43|10@1+ (0.1,0) [0|102.3] "C" Vector__XXX
 SG_ BMS_Temperatures_H6 m7 : 53|10@1+ (0.1,0) [0|102.3] "C" Vector__XXX

BO_ 800 BMS_DrainStatus: 8 BMS
 SG_ BMS_DrainStatus M : 0|2@1+ (1,0) [0|3] "" Vector__XXX
 SG_ BMS_DrainStatus_A1 m0 : 3|1@1+ (1,0) [0|1] "" Vector__XXX
 SG_ BMS_DrainStatus_A2 m0 : 4|1@1+ (1,0) [0|1] "" Vector__XXX
 SG_ BMS_DrainStatus_A3 m0 : 5|1@1+ (1,0) [0|1] "" Vector__XXX
 SG_ BMS_DrainStatus_A4 m0 : 6|1@1+ (1,0) [0|1] "" Vector__XXX
 SG_ BMS_DrainStatus_A5 m0 : 7|1@1+ (1,0) [0|1] "" Vector__XXX
 SG_ BMS_DrainStatus_A6 m0 : 8|1@1+ (1,0) [0|1] "" Vector__XXX
 SG_ BMS_DrainStatus_A7 m0 : 9|1@1+ (1,0) [0|1] "" Vector__XXX
 SG_ BMS_DrainStatus_A8 m0 : 10|1@1+ (1,0) [0|1] "" Vector__XXX
 SG_ BMS_DrainStatus_A9 m0 : 11|1@1+ (1,0) [0|1] "" Vector__XXX
 SG_ BMS_DrainStatus_A10 m0 : 12|1@1+ (1,0) [0|1] "" Vector__XXX
 SG_ BMS_DrainStatus_A11 m0 : 13|1@1+ (1,0) [0|1] "" Vector__XXX
 SG_ BMS_DrainStatus_A12 m0 : 14|1@1+ (1,0) [0|1] "" Vector__XXX
 SG_ BMS_DrainStatus_A13 m0 : 15|1@1+ (1,0) [0|1] "" Vector__XXX
 SG_ BMS_DrainStatus_A14 m0 : 16|1@1+ (1,0) [0|1] "" Vector__XXX
 SG_ BMS_DrainStatus_A15 m0 : 17|1@1+ (1,0) [0|1] "" Vector__XXX
 SG_ BMS_DrainStatus_A16 m0 : 18|1@1+ (1,0) [0|1] "" Vector__XXX
 SG_ BMS_DrainStatus_A17 m0 : 19|1@1+ (1,0) [0|1] "" Vector__XXX
 SG_ BMS_DrainStatus_B1 m0 : 20|1@1+ (1,0) [0|1] "" Vector__XXX
 SG_ BMS_DrainStatus_B2 m0 : 21|1@1+ (1,0) [0|1] "" Vector__XXX
 SG_ BMS_DrainStatus_B3 m0 : 22|1@1+ (1,0) [0|1] "" Vector__XXX
 SG_ BMS_DrainStatus_B4 m0 : 23|1@1+ (1,0) [0|1] "" Vector__XXX
 SG_ BMS_DrainStatus_B5 m0 : 24|1@1+ (1,0) [0|1] "" Vector__XXX
 SG_ BMS_DrainStatus_B6 m0 : 25|1@1+ (1,0) [0|1] "" Vector__XXX
 SG_ BMS_DrainStatus_B7 m0 : 26|1@1+ (1,0) [0|1] "" Vector__XXX
 SG_ BMS_DrainStatus_B8 m0 : 27|1@1+ (1,0) [0|1] "" Vector__XXX
 SG_ BMS_DrainStatus_B9 m0 : 28|1@1+ (1,0) [0|1] "" Vector__XXX
 SG_ BMS_DrainStatus_B10 m0 : 29|1@1+ (1,0) [0|1] "" Vector__XXX
 SG_ BMS_DrainStatus_B11 m0 : 30|1@1+ (1,0) [0|1] "" Vector__XXX
 SG_ BMS_DrainStatus_B12 m0 : 31|1@1+ (1,0) [0|1] "" Vector__XXX
 SG_ BMS_DrainStatus_B13 m0 : 32|1@1+ (1,0) [0|1] "" Vector__XXX
 SG_ BMS_DrainStatus_B14 m0 : 33|1@1+ (1,0) [0|1] "" Vector__XXX
 SG_ BMS_DrainStatus_B15 m0 : 34|1@1+ (1,0) [0|1] "" Vector__XXX
 SG_ BMS_DrainStatus_B16 m0 : 35|1@1+ (1,0) [0|1] "" Vector__XXX
 SG_ BMS_DrainStatus_B17 m0 : 36|1@1+ (1,0) [0|1] "" Vector__XXX
 SG_ BMS_DrainStatus_C1 m0 : 37|1@1+ (1,0) [0|1] "" Vector__XXX
 SG_ BMS_DrainStatus_C2 m0 : 38|1@1+ (1,0) [0|1] "" Vector__XXX
 SG_ BMS_DrainStatus_C3 m0 : 39|1@1+ (1,0) [0|1] "" Vector__XXX
 SG_ BMS_DrainStatus_C4 m0 : 40|1@1+ (1,0) [0|1] "" Vector__XXX
 SG_ BMS_DrainStatus_C5 m0 : 41|1@1+ (1,0) [0|1] "" Vector__XXX
 SG_ BMS_DrainStatus_C6 m0 : 42|1@1+ (1,0) [0|1] "" Vector__XXX
 SG_ BMS_DrainStatus_C7 m0 : 43|1@1+ (1,0) [0|1] "" Vector__XXX
 SG_ BMS_DrainStatus_C8 m0 : 44|1@1+ (1,0) [0|1] "" Vector__XXX
 SG_ BMS_DrainStatus_C9 m0 : 45|1@1+ (1,0) [0|1] "" Vector__XXX
 SG_ BMS_DrainStatus_C10 m0 : 46|1@1+ (1,0) [0|1] "" Vector__XXX
 SG_ BMS_DrainStatus_C11 m0 : 47|1@1+ (1,0) [0|1] "" Vector__XXX
 SG_ BMS_DrainStatus_C12 m0 : 48|1@1+ (1,0) [0|1] "" Vector__XXX
 SG_ BMS_DrainStatus_C13 m0 : 49|1@1+ (1,0) [0|1] "" Vector__XXX
 SG_ BMS_DrainStatus_C14 m0 : 50|1@1+ (1,0) [0|1] "" Vector__XXX
 SG_ BMS_DrainStatus_C15 m0 : 51|1@1+ (1,0) [0|1] "" Vector__XXX
 SG_ BMS_DrainStatus_C16 m0 : 52|1@1+ (1,0) [0|1] "" Vector__XXX
 SG_ BMS_DrainStatus_C17 m0 : 53|1@1+ (1,0) [0|1] "" Vector__XXX
 SG_ BMS_DrainStatus_D1 m0 : 54|1@1+ (1,0) [0|1] "" Vector__XXX
 SG_ BMS_DrainStatus_D2 m0 : 55|1@1+ (1,0) [0|1] "" Vector__XXX
 SG_ BMS_DrainStatus_D3 m0 : 56|1@1+ (1,0) [0|1] "" Vector__XXX
 SG_ BMS_DrainStatus_D4 m0 : 57|1@1+ (1,0) [0|1] "" Vector__XXX
 SG_ BMS_DrainStatus_D5 m0 : 58|1@1+ (1,0) [0|1] "" Vector__XXX
 SG_ BMS_DrainStatus_D6 m0 : 59|1@1+ (1,0) [0|1] "" Vector__XXX
 SG_ BMS_DrainStatus_D7 m0 : 60|1@1+ (1,0) [0|1] "" Vector__XXX
 SG_ BMS_DrainStatus_D8 m0 : 61|1@1+ (1,0) [0|1] "" Vector__XXX
 SG_ BMS_DrainStatus_D9 m0 : 62|1@1+ (1,0) [0|1] "" Vector__XXX
 SG_ BMS_DrainStatus_D10 m0 : 63|1@1+ (1,0) [0|1] "" Vector__XXX
 SG_ BMS_DrainStatus_D11 m1 : 3|1@1+ (1,0) [0|1] "" Vector__XXX
 SG_ BMS_DrainStatus_D12 m1 : 4|1@1+ (1,0) [0|1] "" Vector__XXX
 SG_ BMS_DrainStatus_D13 m1 : 5|1@1+ (1,0) [0|1] "" Vector__XXX
 SG_ BMS_DrainStatus_D14 m1 : 6|1@1+ (1,0) [0|1] "" Vector__XXX
 SG_ BMS_DrainStatus_D15 m1 : 7|1@1+ (1,0) [0|1] "" Vector__XXX
 SG_ BMS_DrainStatus_D16 m1 : 8|1@1+ (1,0) [0|1] "" Vector__XXX
 SG_ BMS_DrainStatus_D17 m1 : 9|1@1+ (1,0) [0|1] "" Vector__XXX
 SG_ BMS_DrainStatus_E1 m1 : 10|1@1+ (1,0) [0|1] "" Vector__XXX
 SG_ BMS_DrainStatus_E2 m1 : 11|1@1+ (1,0) [0|1] "" Vector__XXX
 SG_ BMS_DrainStatus_E3 m1 : 12|1@1+ (1,0) [0|1] "" Vector__XXX
 SG_ BMS_DrainStatus_E4 m1 : 13|1@1+ (1,0) [0|1] "" Vector__XXX
 SG_ BMS_DrainStatus_E5 m1 : 14|1@1+ (1,0) [0|1] "" Vector__XXX
 SG_ BMS_DrainStatus_E6 m1 : 15|1@1+ (1,0) [0|1] "" Vector__XXX
 SG_ BMS_DrainStatus_E7 m1 : 16|1@1+ (1,0) [0|1] "" Vector__XXX
 SG_ BMS_DrainStatus_E8 m1 : 17|1@1+ (1,0) [0|1] "" Vector__XXX
 SG_ BMS_DrainStatus_E9 m1 : 18|1@1+ (1,0) [0|1] "" Vector__XXX
 SG_ BMS_DrainStatus_E10 m1 : 19|1@1+ (1,0) [0|1] "" Vector__XXX
 SG_ BMS_DrainStatus_E11 m1 : 20|1@1+ (1,0) [0|1] "" Vector__XXX
 SG_ BMS_DrainStatus_E12 m1 : 21|1@1+ (1,0) [0|1] "" Vector__XXX
 SG_ BMS_DrainStatus_E13 m1 : 22|1@1+ (1,0) [0|1] "" Vector__XXX
 SG_ BMS_DrainStatus_E14 m1 : 23|1@1+ (1,0) [0|1] "" Vector__XXX
 SG_ BMS_DrainStatus_E15 m1 : 24|1@1+ (1,0) [0|1] "" Vector__XXX
 SG_ BMS_DrainStatus_E16 m1 : 25|1@1+ (1,0) [0|1] "" Vector__XXX
 SG_ BMS_DrainStatus_E17 m1 : 26|1@1+ (1,0) [0|1] "" Vector__XXX
 SG_ BMS_DrainStatus_F1 m1 : 27|1@1+ (1,0) [0|1] "" Vector__XXX
 SG_ BMS_DrainStatus_F2 m1 : 28|1@1+ (1,0) [0|1] "" Vector__XXX
 SG_ BMS_DrainStatus_F3 m1 : 29|1@1+ (1,0) [0|1] "" Vector__XXX
 SG_ BMS_DrainStatus_F4 m1 : 30|1@1+ (1,0) [0|1] "" Vector__XXX
 SG_ BMS_DrainStatus_F5 m1 : 31|1@1+ (1,0) [0|1] "" Vector__XXX
 SG_ BMS_DrainStatus_F6 m1 : 32|1@1+ (1,0) [0|1] "" Vector__XXX
 SG_ BMS_DrainStatus_F7 m1 : 33|1@1+ (1,0) [0|1] "" Vector__XXX
 SG_ BMS_DrainStatus_F8 m1 : 34|1@1+ (1,0) [0|1] "" Vector__XXX
 SG_ BMS_DrainStatus_F9 m1 : 35|1@1+ (1,0) [0|1] "" Vector__XXX
 SG_ BMS_DrainStatus_F10 m1 : 36|1@1+ (1,0) [0|1] "" Vector__XXX
 SG_ BMS_DrainStatus_F11 m1 : 37|1@1+ (1,0) [0|1] "" Vector__XXX
 SG_ BMS_DrainStatus_F12 m1 : 38|1@1+ (1,0) [0|1] "" Vector__XXX
 SG_ BMS_DrainStatus_F13 m1 : 39|1@1+ (1,0) [0|1] "" Vector__XXX
 SG_ BMS_DrainStatus_F14 m1 : 40|1@1+ (1,0) [0|1] "" Vector__XXX
 SG_ BMS_DrainStatus_F15 m1 : 41|1@1+ (1,0) [0|1] "" Vector__XXX
 SG_ BMS_DrainStatus_F16 m1 : 42|1@1+ (1,0) [0|1] "" Vector__XXX
 SG_ BMS_DrainStatus_F17 m1 : 43|1@1+ (1,0) [0|1] "" Vector__XXX
 SG_ BMS_DrainStatus_G1 m1 : 44|1@1+ (1,0) [0|1] "" Vector__XXX
 SG_ BMS_DrainStatus_G2 m1 : 45|1@1+ (1,0) [0|1] "" Vector__XXX
 SG_ BMS_DrainStatus_G3 m1 : 46|1@1+ (1,0) [0|1] "" Vector__XXX
 SG_ BMS_DrainStatus_G4 m1 : 47|1@1+ (1,0) [0|1] "" Vector__XXX
 SG_ BMS_DrainStatus_G5 m1 : 48|1@1+ (1,0) [0|1] "" Vector__XXX
 SG_ BMS_DrainStatus_G6 m1 : 49|1@1+ (1,0) [0|1] "" Vector__XXX
 SG_ BMS_DrainStatus_G7 m1 : 50|1@1+ (1,0) [0|1] "" Vector__XXX
 SG_ BMS_DrainStatus_G8 m1 : 51|1@1+ (1,0) [0|1] "" Vector__XXX
 SG_ BMS_DrainStatus_G9 m1 : 52|1@1+ (1,0) [0|1] "" Vector__XXX
 SG_ BMS_DrainStatus_G10 m1 : 53|1@1+ (1,0) [0|1] "" Vector__XXX
 SG_ BMS_DrainStatus_G11 m1 : 54|1@1+ (1,0) [0|1] "" Vector__XXX
 SG_ BMS_DrainStatus_G12 m1 : 55|1@1+ (1,0) [0|1] "" Vector__XXX
 SG_ BMS_DrainStatus_G13 m1 : 56|1@1+ (1,0) [0|1] "" Vector__XXX
 SG_ BMS_DrainStatus_G14 m1 : 57|1@1+ (1,0) [0|1] "" Vector__XXX
 SG_ BMS_DrainStatus_G15 m1 : 58|1@1+ (1,0) [0|1] "" Vector__XXX
 SG_ BMS_DrainStatus_G16 m1 : 59|1@1+ (1,0) [0|1] "" Vector__XXX
 SG_ BMS_DrainStatus_G17 m1 : 60|1@1+ (1,0) [0|1] "" Vector__XXX
 SG_ BMS_DrainStatus_H1 m1 : 61|1@1+ (1,0) [0|1] "" Vector__XXX
 SG_ BMS_DrainStatus_H2 m1 : 62|1@1+ (1,0) [0|1] "" Vector__XXX
 SG_ BMS_DrainStatus_H3 m1 : 63|1@1+ (1,0) [0|1] "" Vector__XXX
 SG_ BMS_DrainStatus_H4 m2 : 3|1@1+ (1,0) [0|1] "" Vector__XXX
 SG_ BMS_DrainStatus_H5 m2 : 4|1@1+ (1,0) [0|1] "" Vector__XXX
 SG_ BMS_DrainStatus_H6 m2 : 5|1@1+ (1,0) [0|1] "" Vector__XXX
 SG_ BMS_DrainStatus_H7 m2 : 6|1@1+ (1,0) [0|1] "" Vector__XXX
 SG_ BMS_DrainStatus_H8 m2 : 7|1@1+ (1,0) [0|1] "" Vector__XXX
 SG_ BMS_DrainStatus_H9 m2 : 8|1@1+ (1,0) [0|1] "" Vector__XXX
 SG_ BMS_DrainStatus_H10 m2 : 9|1@1+ (1,0) [0|1] "" Vector__XXX
 SG_ BMS_DrainStatus_H11 m2 : 10|1@1+ (1,0) [0|1] "" Vector__XXX
 SG_ BMS_DrainStatus_H12 m2 : 11|1@1+ (1,0) [0|1] "" Vector__XXX
 SG_ BMS_DrainStatus_H13 m2 : 12|1@1+ (1,0) [0|1] "" Vector__XXX
 SG_ BMS_DrainStatus_H14 m2 : 13|1@1+ (1,0) [0|1] "" Vector__XXX
 SG_ BMS_DrainStatus_H15 m2 : 14|1@1+ (1,0) [0|1] "" Vector__XXX
 SG_ BMS_DrainStatus_H16 m2 : 15|1@1+ (1,0) [0|1] "" Vector__XXX
 SG_ BMS_DrainStatus_H17 m2 : 16|1@1+ (1,0) [0|1] "" Vector__XXX

BO_ 900 BMS_Current: 8 BMS
 SG_ BMS_InstCurrentFilt : 0|32@1- (0.001,0) [-100|250] "A"  DASH

BO_ 950 BMS_HardFaultIndicator: 8 BMS
 SG_ BMS_HardFaultIndicator_task : 0|4@1+ (1,0) [0|15] "" Vector__XXX

BO_ 951 BMS_Ref: 8 BMS
 SG_ BMS_Ref_mux M : 0|1@1+ (1,0) [0|1] "" Vector__XXX
 SG_ BMS_Ref_ref0 m0 : 1|9@1+ (0.01,0) [0|5.12] "V" Vector__XXX
 SG_ BMS_Ref_ref1 m0 : 10|9@1+ (0.01,0) [0|5.12] "V" Vector__XXX
 SG_ BMS_Ref_ref2 m0 : 19|9@1+ (0.01,0) [0|5.12] "V" Vector__XXX
 SG_ BMS_Ref_ref3 m0 : 28|9@1+ (0.01,0) [0|5.12] "V" Vector__XXX
 SG_ BMS_Ref_ref4 m0 : 37|9@1+ (0.01,0) [0|5.12] "V" Vector__XXX
 SG_ BMS_Ref_ref5 m0 : 46|9@1+ (0.01,0) [0|5.12] "V" Vector__XXX
 SG_ BMS_Ref_ref6 m1 : 1|9@1+ (0.01,0) [0|5.12] "V" Vector__XXX
 SG_ BMS_Ref_ref7 m1 : 10|9@1+ (0.01,0) [0|5.12] "V" Vector__XXX
 SG_ BMS_Ref_ref8 m1 : 19|9@1+ (0.01,0) [0|5.12] "V" Vector__XXX
 SG_ BMS_Ref_ref9 m1 : 28|9@1+ (0.01,0) [0|5.12] "V" Vector__XXX
 SG_ BMS_Ref_ref10 m1 : 37|9@1+ (0.01,0) [0|5.12] "V" Vector__XXX
 SG_ BMS_Ref_ref11 m1 : 46|9@1+ (0.01,0) [0|5.12] "V" Vector__XXX

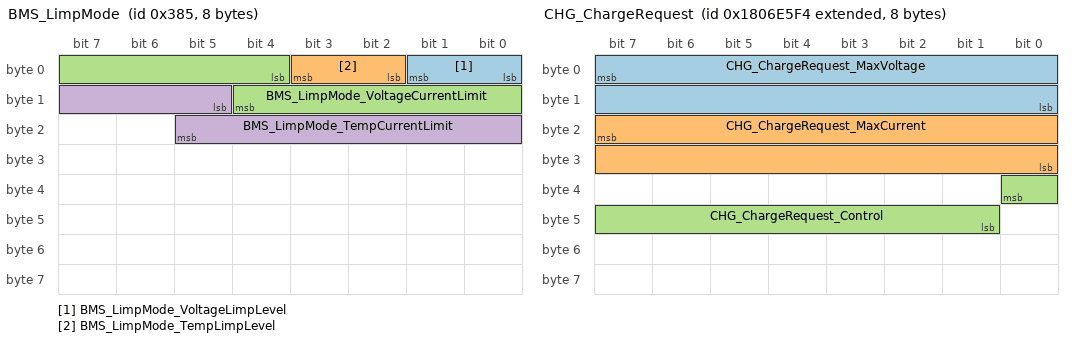
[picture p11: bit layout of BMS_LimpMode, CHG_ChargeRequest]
BO_ 901 BMS_LimpMode: 8 BMS
 SG_ BMS_LimpMode_VoltageLimpLevel : 0|2@1+ (1,0) [0|4] "" Vector__XXX
 SG_ BMS_LimpMode_TempLimpLevel : 2|2@1+ (1,0) [0|4] "" Vector__XXX
 SG_ BMS_LimpMode_VoltageCurrentLimit : 4|9@1- (1,0) [-100|500] "A" Vector__XXX
 SG_ BMS_LimpMode_TempCurrentLimit : 13|9@1- (1,0) [-100|500] "A" Vector__XXX

BO_ 2550588916 CHG_ChargeRequest: 8 BMS
 SG_ CHG_ChargeRequest_MaxVoltage : 7|16@0+ (0.1,0) [0|6553.5] "V"  CHG
 SG_ CHG_ChargeRequest_MaxCurrent : 23|16@0+ (0.1,0) [0|6553.5] "A"  CHG
 SG_ CHG_ChargeRequest_Control : 32|8@0+ (1,0) [0|1] ""  CHG

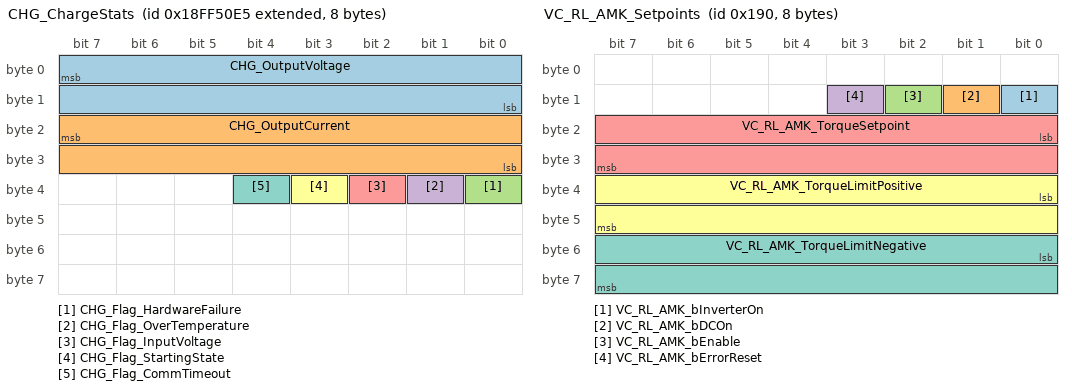
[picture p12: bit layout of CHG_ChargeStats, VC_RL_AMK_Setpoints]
BO_ 2566869221 CHG_ChargeStats: 8 CHG
 SG_ CHG_OutputVoltage : 7|16@0+ (0.1,0) [0|6553.5] "V" Vector__XXX
 SG_ CHG_OutputCurrent : 23|16@0+ (0.1,0) [0|6553.5] "A" Vector__XXX
 SG_ CHG_Flag_HardwareFailure : 32|1@1+ (1,0) [0|1] "" Vector__XXX
 SG_ CHG_Flag_OverTemperature : 33|1@1+ (1,0) [0|1] "" Vector__XXX
 SG_ CHG_Flag_InputVoltage : 34|1@1+ (1,0) [0|1] "" Vector__XXX
 SG_ CHG_Flag_StartingState : 35|1@1+ (1,0) [0|1] "" Vector__XXX
 SG_ CHG_Flag_CommTimeout : 36|1@1+ (1,0) [0|1] "" Vector__XXX

BO_ 504 SSDB_front: 3 SSDB
 SG_ SSDB_brake_pressure_front_raw : 0|12@1+ (1,0) [0|4095] "" Vector__XXX
 SG_ SSDB_steering_angle_raw : 12|12@1+ (1,0) [0|4095] "" Vector__XXX

BO_ 400 VC_RL_AMK_Setpoints: 8 VC
 SG_ VC_RL_AMK_bInverterOn : 8|1@1+ (1,0) [0|1] "" Vector__XXX
 SG_ VC_RL_AMK_bDCOn : 9|1@1+ (1,0) [0|1] "" Vector__XXX
 SG_ VC_RL_AMK_bEnable : 10|1@1+ (1,0) [0|1] "" Vector__XXX
 SG_ VC_RL_AMK_bErrorReset : 11|1@1+ (1,0) [0|1] "" Vector__XXX
 SG_ VC_RL_AMK_TorqueSetpoint : 16|16@1- (0.1, 0) [-1000|1000] "% Mn" Vector__XXX
 SG_ VC_RL_AMK_TorqueLimitPositive : 32|16@1- (0.1, 0) [-3000|3000] "% Mn" Vector__XXX
 SG_ VC_RL_AMK_TorqueLimitNegative : 48|16@1- (0.1, 0) [-3000|3000] "% Mn" Vector__XXX

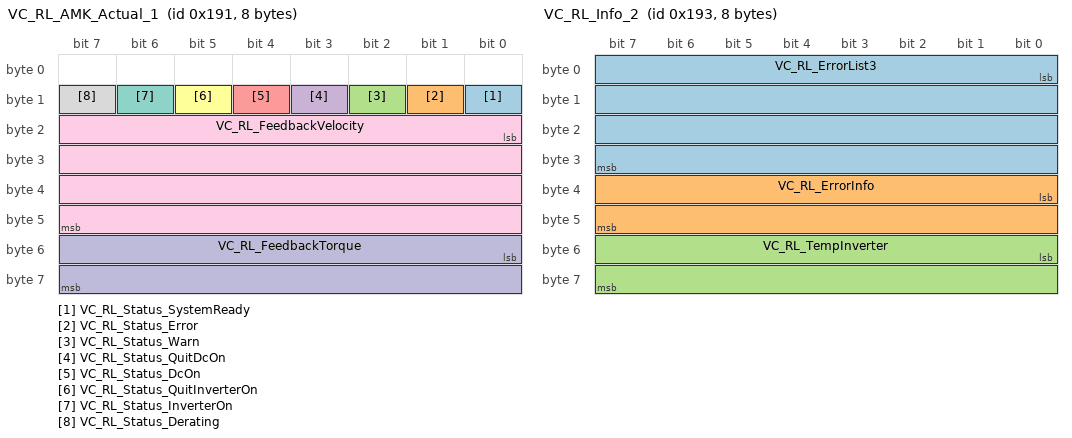
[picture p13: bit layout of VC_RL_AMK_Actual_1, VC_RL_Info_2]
BO_ 401 VC_RL_AMK_Actual_1: 8 VC
 SG_ VC_RL_Status_SystemReady : 8|1@1+ (1,0) [0|1] "" Vector__XXX
 SG_ VC_RL_Status_Error : 9|1@1+ (1,0) [0|1] "" Vector__XXX
 SG_ VC_RL_Status_Warn : 10|1@1+ (1,0) [0|1] "" Vector__XXX
 SG_ VC_RL_Status_QuitDcOn : 11|1@1+ (1,0) [0|1] "" Vector__XXX
 SG_ VC_RL_Status_DcOn : 12|1@1+ (1,0) [0|1] "" Vector__XXX
 SG_ VC_RL_Status_QuitInverterOn : 13|1@1+ (1,0) [0|1] "" Vector__XXX
 SG_ VC_RL_Status_InverterOn : 14|1@1+ (1,0) [0|1] "" Vector__XXX
 SG_ VC_RL_Status_Derating : 15|1@1+ (1,0) [0|1] "" Vector__XXX
 SG_ VC_RL_FeedbackVelocity : 16|32@1- (0.0001,0) [-100000.0|100000.0] "rpm" Vector__XXX
 SG_ VC_RL_FeedbackTorque : 48|16@1- (0.1,0) [-3000.0|3000.0] "% Mn" Vector__XXX

BO_ 402 VC_RL_Info_1: 8 VC
 SG_ VC_RL_ErrorList1 : 0|32@1+ (1,0) [0|0] "" Vector__XXX
 SG_ VC_RL_ErrorList2 : 32|32@1+ (1,0) [0|0] "" Vector__XXX

BO_ 403 VC_RL_Info_2: 8 VC
 SG_ VC_RL_ErrorList3 : 0|32@1+ (1,0) [0|0] "" Vector__XXX
 SG_ VC_RL_ErrorInfo : 32|16@1+ (1,0) [0|65535] "" Vector__XXX
 SG_ VC_RL_TempInverter : 48|16@1- (0.1,0) [-3276.8|3276.7] "degC" Vector__XXX

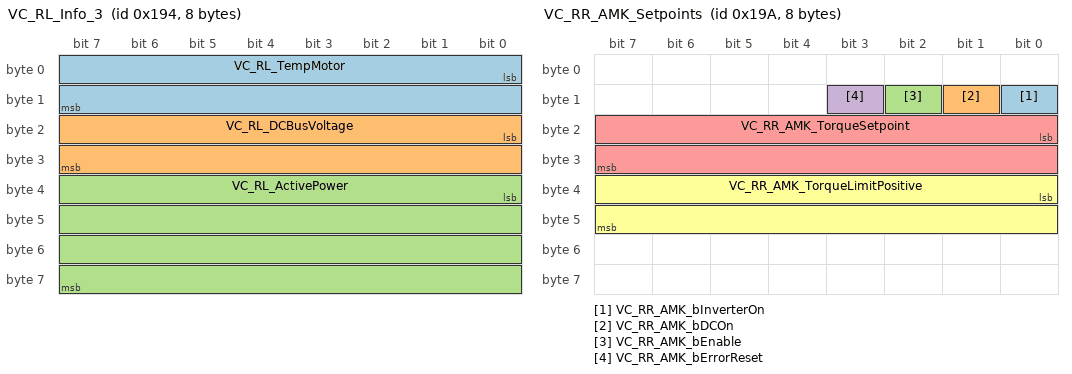
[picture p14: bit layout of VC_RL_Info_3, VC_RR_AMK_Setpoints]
BO_ 404 VC_RL_Info_3: 8 VC
 SG_ VC_RL_TempMotor : 0|16@1- (0.1,0) [-3276.8|3276.7] "degC" Vector__XXX
 SG_ VC_RL_DCBusVoltage : 16|16@1+ (1,0) [0|4096] "V" Vector__XXX
 SG_ VC_RL_ActivePower : 32|32@1- (1,0) [-32768|32767] "W" Vector__XXX

BO_ 405 VC_RL_AMK_RITSet4: 4 VC
 SG_ RL_ActualPowerBipolar : 0|32@1- (1,0) [0|0] "W" Vector__XXX

BO_ 406 VC_RL_AMK_RIT_Set5: 4 VC
 SG_ RL_MagnetizingCurrent: 0|32@1- (0.001,0) [0|0] "A" Vector__XXX

BO_ 407 VC_RL_AMK_RIT_Set6: 4 VC
 SG_ RL_TorqueCurrentFeedback: 0|32@1- (0.001,0) [0|0] "A" Vector__XXX

BO_ 410 VC_RR_AMK_Setpoints: 8 VC
 SG_ VC_RR_AMK_bInverterOn : 8|1@1+ (1,0) [0|1] "" Vector__XXX
 SG_ VC_RR_AMK_bDCOn : 9|1@1+ (1,0) [0|1] "" Vector__XXX
 SG_ VC_RR_AMK_bEnable : 10|1@1+ (1,0) [0|1] "" Vector__XXX
 SG_ VC_RR_AMK_bErrorReset : 11|1@1+ (1,0) [0|1] "" Vector__XXX
 SG_ VC_RR_AMK_TorqueSetpoint : 16|16@1- (0.1, 0) [-1000|1000] "% Mn" Vector__XXX
 SG_ VC_RR_AMK_TorqueLimitPositive : 32|16@1- (0.1, 0) [-3000|3000] "% Mn" Vector__XXX

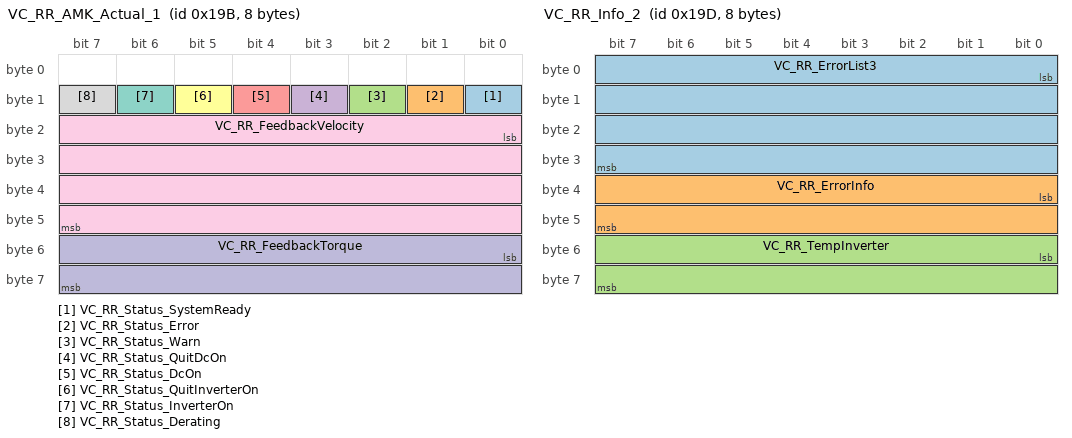
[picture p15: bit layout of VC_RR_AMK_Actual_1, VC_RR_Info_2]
BO_ 411 VC_RR_AMK_Actual_1: 8 VC
 SG_ VC_RR_Status_SystemReady : 8|1@1+ (1,0) [0|1] "" Vector__XXX
 SG_ VC_RR_Status_Error : 9|1@1+ (1,0) [0|1] "" Vector__XXX
 SG_ VC_RR_Status_Warn : 10|1@1+ (1,0) [0|1] "" Vector__XXX
 SG_ VC_RR_Status_QuitDcOn : 11|1@1+ (1,0) [0|1] "" Vector__XXX
 SG_ VC_RR_Status_DcOn : 12|1@1+ (1,0) [0|1] "" Vector__XXX
 SG_ VC_RR_Status_QuitInverterOn : 13|1@1+ (1,0) [0|1] "" Vector__XXX
 SG_ VC_RR_Status_InverterOn : 14|1@1+ (1,0) [0|1] "" Vector__XXX
 SG_ VC_RR_Status_Derating : 15|1@1+ (1,0) [0|1] "" Vector__XXX
 SG_ VC_RR_FeedbackVelocity : 16|32@1- (0.0001,0) [-100000.0|100000.0] "rpm" Vector__XXX
 SG_ VC_RR_FeedbackTorque : 48|16@1- (0.1,0) [-3000.0|3000.0] "% Mn" Vector__XXX

BO_ 412 VC_RR_Info_1: 8 VC
 SG_ VC_RR_ErrorList1 : 0|32@1+ (1,0) [0|0] "" Vector__XXX
 SG_ VC_RR_ErrorList2 : 32|32@1+ (1,0) [0|0] "" Vector__XXX

BO_ 413 VC_RR_Info_2: 8 VC
 SG_ VC_RR_ErrorList3 : 0|32@1+ (1,0) [0|0] "" Vector__XXX
 SG_ VC_RR_ErrorInfo : 32|16@1+ (1,0) [0|65535] "" Vector__XXX
 SG_ VC_RR_TempInverter : 48|16@1- (0.1,0) [-3276.8|3276.7] "degC" Vector__XXX

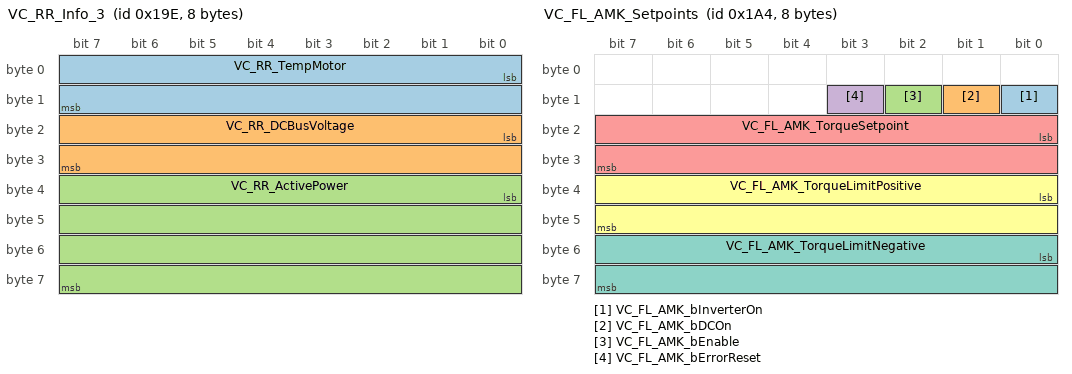
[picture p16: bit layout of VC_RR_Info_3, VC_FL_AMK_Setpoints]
BO_ 414 VC_RR_Info_3: 8 VC
 SG_ VC_RR_TempMotor : 0|16@1- (0.1,0) [-3276.8|3276.7] "degC" Vector__XXX
 SG_ VC_RR_DCBusVoltage : 16|16@1+ (1,0) [0|4096] "V" Vector__XXX
 SG_ VC_RR_ActivePower : 32|32@1- (1,0) [-32768|32767] "W" Vector__XXX

BO_ 415 VC_RR_AMK_RITSet4: 4 VC
 SG_ RR_ActualPowerBipolar : 0|32@1- (1,0) [0|0] "W" Vector__XXX

BO_ 416 VC_RR_AMK_RIT_Set5: 4 VC
 SG_ RR_MagnetizingCurrent: 0|32@1- (0.001,0) [0|0] "A" Vector__XXX

BO_ 417 VC_RR_AMK_RIT_Set6: 4 VC
 SG_ RR_TorqueCurrentFeedback: 0|32@1- (0.001,0) [0|0] "A" Vector__XXX

BO_ 420 VC_FL_AMK_Setpoints: 8 VC
 SG_ VC_FL_AMK_bInverterOn : 8|1@1+ (1,0) [0|1] "" Vector__XXX
 SG_ VC_FL_AMK_bDCOn : 9|1@1+ (1,0) [0|1] "" Vector__XXX
 SG_ VC_FL_AMK_bEnable : 10|1@1+ (1,0) [0|1] "" Vector__XXX
 SG_ VC_FL_AMK_bErrorReset : 11|1@1+ (1,0) [0|1] "" Vector__XXX
 SG_ VC_FL_AMK_TorqueSetpoint : 16|16@1- (0.1, 0) [-1000|1000] "% Mn" Vector__XXX
 SG_ VC_FL_AMK_TorqueLimitPositive : 32|16@1- (0.1, 0) [-3000|3000] "% Mn" Vector__XXX
 SG_ VC_FL_AMK_TorqueLimitNegative : 48|16@1- (0.1, 0) [-3000|3000] "% Mn" Vector__XXX

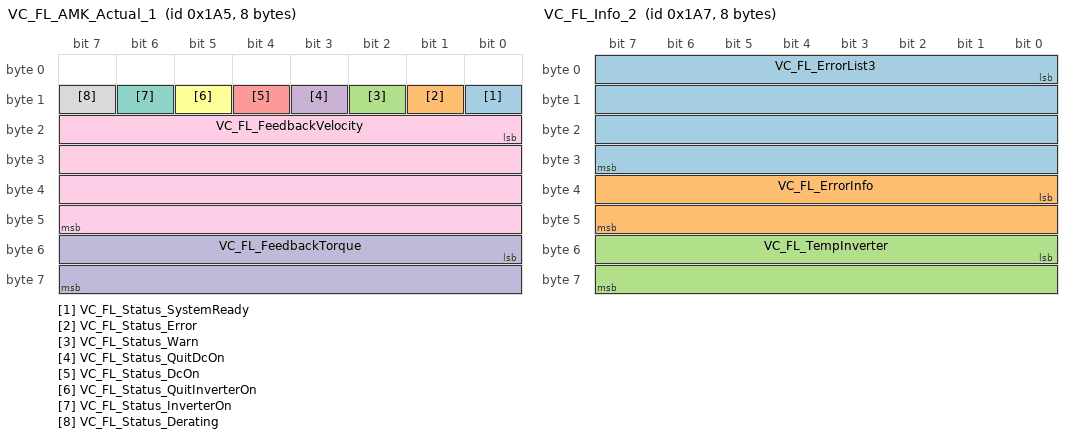
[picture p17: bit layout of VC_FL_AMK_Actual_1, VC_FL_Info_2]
BO_ 421 VC_FL_AMK_Actual_1: 8 VC
 SG_ VC_FL_Status_SystemReady : 8|1@1+ (1,0) [0|1] "" Vector__XXX
 SG_ VC_FL_Status_Error : 9|1@1+ (1,0) [0|1] "" Vector__XXX
 SG_ VC_FL_Status_Warn : 10|1@1+ (1,0) [0|1] "" Vector__XXX
 SG_ VC_FL_Status_QuitDcOn : 11|1@1+ (1,0) [0|1] "" Vector__XXX
 SG_ VC_FL_Status_DcOn : 12|1@1+ (1,0) [0|1] "" Vector__XXX
 SG_ VC_FL_Status_QuitInverterOn : 13|1@1+ (1,0) [0|1] "" Vector__XXX
 SG_ VC_FL_Status_InverterOn : 14|1@1+ (1,0) [0|1] "" Vector__XXX
 SG_ VC_FL_Status_Derating : 15|1@1+ (1,0) [0|1] "" Vector__XXX
 SG_ VC_FL_FeedbackVelocity : 16|32@1- (0.0001,0) [-100000.0|100000.0] "rpm" Vector__XXX
 SG_ VC_FL_FeedbackTorque : 48|16@1- (0.1,0) [-3000.0|3000.0] "% Mn" Vector__XXX

BO_ 422 VC_Fl_Info_1: 8 VC
 SG_ VC_FL_ErrorList1 : 0|32@1+ (1,0) [0|0] "" Vector__XXX
 SG_ VC_FL_ErrorList2 : 32|32@1+ (1,0) [0|0] "" Vector__XXX

BO_ 423 VC_FL_Info_2: 8 VC
 SG_ VC_FL_ErrorList3 : 0|32@1+ (1,0) [0|0] "" Vector__XXX
 SG_ VC_FL_ErrorInfo : 32|16@1+ (1,0) [0|65535] "" Vector__XXX
 SG_ VC_FL_TempInverter : 48|16@1- (0.1,0) [-3276.8|3276.7] "degC" Vector__XXX

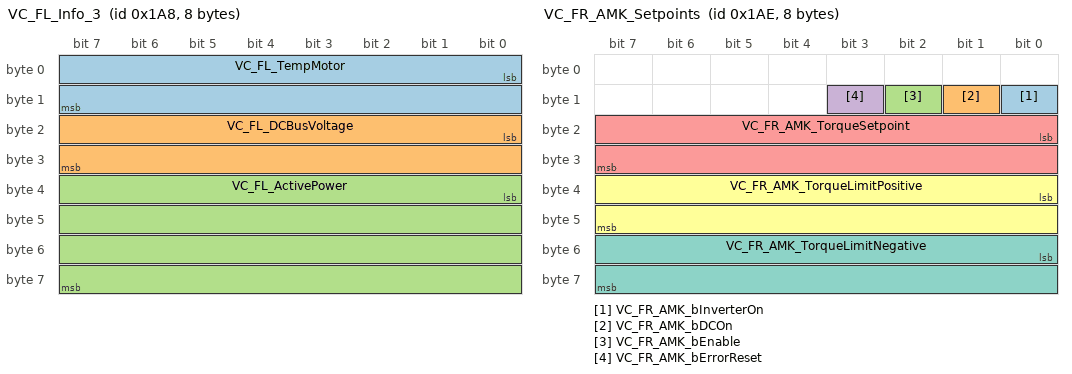
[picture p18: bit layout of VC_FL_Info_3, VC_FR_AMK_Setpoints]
BO_ 424 VC_FL_Info_3: 8 VC
 SG_ VC_FL_TempMotor : 0|16@1- (0.1,0) [-3276.8|3276.7] "degC" Vector__XXX
 SG_ VC_FL_DCBusVoltage : 16|16@1+ (1,0) [0|4096] "V" Vector__XXX
 SG_ VC_FL_ActivePower : 32|32@1- (1,0) [-32768|32767] "W" Vector__XXX

BO_ 425 VC_FL_AMK_RITSet4: 4 VC
 SG_ FL_ActualPowerBipolar : 0|32@1- (1,0) [0|0] "W" Vector__XXX

BO_ 426 VC_FL_AMK_RIT_Set5: 4 VC
 SG_ FL_MagnetizingCurrent: 0|32@1- (0.001,0) [0|0] "A" Vector__XXX

BO_ 427 VC_FL_AMK_RIT_Set6: 4 VC
 SG_ FL_TorqueCurrentFeedback: 0|32@1- (0.001,0) [0|0] "A" Vector__XXX

BO_ 430 VC_FR_AMK_Setpoints: 8 VC
 SG_ VC_FR_AMK_bInverterOn : 8|1@1+ (1,0) [0|1] "" Vector__XXX
 SG_ VC_FR_AMK_bDCOn : 9|1@1+ (1,0) [0|1] "" Vector__XXX
 SG_ VC_FR_AMK_bEnable : 10|1@1+ (1,0) [0|1] "" Vector__XXX
 SG_ VC_FR_AMK_bErrorReset : 11|1@1+ (1,0) [0|1] "" Vector__XXX
 SG_ VC_FR_AMK_TorqueSetpoint : 16|16@1- (0.1, 0) [-1000|1000] "% Mn" Vector__XXX
 SG_ VC_FR_AMK_TorqueLimitPositive : 32|16@1- (0.1, 0) [-3000|3000] "% Mn" Vector__XXX
 SG_ VC_FR_AMK_TorqueLimitNegative : 48|16@1- (0.1, 0) [-3000|3000] "% Mn" Vector__XXX

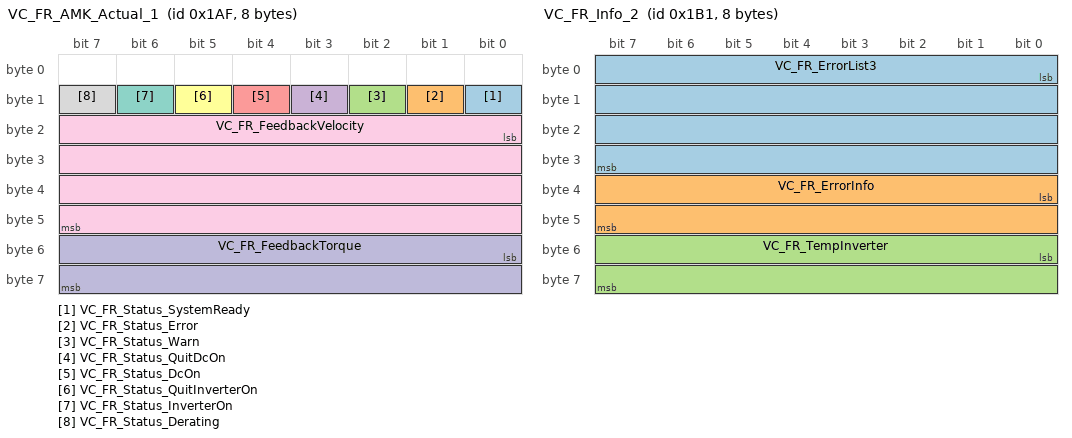
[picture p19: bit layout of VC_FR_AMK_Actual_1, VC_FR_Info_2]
BO_ 431 VC_FR_AMK_Actual_1: 8 VC
 SG_ VC_FR_Status_SystemReady : 8|1@1+ (1,0) [0|1] "" Vector__XXX
 SG_ VC_FR_Status_Error : 9|1@1+ (1,0) [0|1] "" Vector__XXX
 SG_ VC_FR_Status_Warn : 10|1@1+ (1,0) [0|1] "" Vector__XXX
 SG_ VC_FR_Status_QuitDcOn : 11|1@1+ (1,0) [0|1] "" Vector__XXX
 SG_ VC_FR_Status_DcOn : 12|1@1+ (1,0) [0|1] "" Vector__XXX
 SG_ VC_FR_Status_QuitInverterOn : 13|1@1+ (1,0) [0|1] "" Vector__XXX
 SG_ VC_FR_Status_InverterOn : 14|1@1+ (1,0) [0|1] "" Vector__XXX
 SG_ VC_FR_Status_Derating : 15|1@1+ (1,0) [0|1] "" Vector__XXX
 SG_ VC_FR_FeedbackVelocity : 16|32@1- (0.0001,0) [-100000.0|100000.0] "rpm" Vector__XXX
 SG_ VC_FR_FeedbackTorque : 48|16@1- (0.1,0) [-3000.0|3000.0] "% Mn" Vector__XXX

BO_ 432 VC_FR_Info_1: 8 VC
 SG_ VC_FR_ErrorList1 : 0|32@1+ (1,0) [0|0] "" Vector__XXX
 SG_ VC_FR_ErrorList2 : 32|32@1+ (1,0) [0|0] "" Vector__XXX

BO_ 433 VC_FR_Info_2: 8 VC
 SG_ VC_FR_ErrorList3 : 0|32@1+ (1,0) [0|0] "" Vector__XXX
 SG_ VC_FR_ErrorInfo : 32|16@1+ (1,0) [0|65535] "" Vector__XXX
 SG_ VC_FR_TempInverter : 48|16@1- (0.1,0) [-3276.8|3276.7] "degC" Vector__XXX

BO_ 434 VC_FR_Info_3: 8 VC
 SG_ VC_FR_TempMotor : 0|16@1- (0.1,0) [-3276.8|3276.7] "degC" Vector__XXX
 SG_ VC_FR_DCBusVoltage : 16|16@1+ (1,0) [0|4096] "V" Vector__XXX
 SG_ VC_FR_ActivePower : 32|32@1- (1,0) [-32768|32767] "W" Vector__XXX

BO_ 435 VC_FR_AMK_RITSet4: 4 VC
 SG_ FR_ActualPowerBipolar : 0|32@1- (1,0) [0|0] "W" Vector__XXX

BO_ 436 VC_FR_AMK_RIT_Set5: 4 VC
 SG_ FR_MagnetizingCurrent: 0|32@1- (0.001,0) [0|0] "A" Vector__XXX

BO_ 437 VC_FR_AMK_RIT_Set6: 4 VC
 SG_ FR_TorqueCurrentFeedback: 0|32@1- (0.001,0) [0|0] "A" Vector__XXX

BO_ 520 SSDB_suspension_front: 3 SSDB
 SG_ SSDB_suspension_FL : 0|12@1+ (1,0) [0|4095] "" Vector__XXX
 SG_ SSDB_suspension_FR : 12|12@1+ (1,0) [0|4095] "" Vector__XXX

BO_ 521 SSDB_suspension_rear: 3 SSDB
 SG_ SSDB_suspension_RL : 0|12@1+ (1,0) [0|4095] "" Vector__XXX
 SG_ SSDB_suspension_RR : 12|12@1+ (1,0) [0|4095] "" Vector__XXX

BO_ 506 OutboardAccelAvg: 6 OA
 SG_ OAAvg_AccelX : 0|16@1- (0.001,0) [-32.768|32.767] "g" Vector_XXX
 SG_ OAAvg_AccelY : 16|16@1- (0.001,0) [-32.768|32.767] "g" Vector_XXX
 SG_ OAAvg_AccelZ : 32|16@1- (0.001,0) [-32.768|32.767] "g" Vector_XXX

BO_ 507 OutboardAccelMin: 6 OA
 SG_ OAMin_AccelX : 0|16@1- (0.001,0) [-32.768|32.767] "g" Vector_XXX
 SG_ OAMin_AccelY : 16|16@1- (0.001,0) [-32.768|32.767] "g" Vector_XXX
 SG_ OAMin_AccelZ : 32|16@1- (0.001,0) [-32.768|32.767] "g" Vector_XXX

BO_ 508 OutboardAccelMax: 6 OA
 SG_ OAMax_AccelX : 0|16@1- (0.001,0) [-32.768|32.767] "g" Vector_XXX
 SG_ OAMax_AccelY : 16|16@1- (0.001,0) [-32.768|32.767] "g" Vector_XXX
 SG_ OAMax_AccelZ : 32|16@1- (0.001,0) [-32.768|32.767] "g" Vector_XXX

BO_ 530 VectorNav0: 8 VectorNav
 SG_ VectorNav_AccelX : 0|32@1+ (1,0) [0|0] "m/s^2" Vector__XXX
 SG_ VectorNav_AccelY : 32|32@1+ (1,0) [0|0] "m/s^2" Vector__XXX

BO_ 531 VectorNav1: 8 VectorNav
 SG_ VectorNav_AccelZ : 0|32@1+ (1,0) [0|0] "m/s^2" Vector__XXX
 SG_ VectorNav_AngularRateX : 32|32@1+ (1,0) [0|0] "rad/s" Vector__XXX

BO_ 532 VectorNav2: 8 VectorNav
 SG_ VectorNav_AngularRateY : 0|32@1+ (1,0) [0|0] "rad/s" Vector__XXX
 SG_ VectorNav_AngularRateZ : 32|32@1+ (1,0) [0|0] "rad/s" Vector__XXX

BO_ 533 VectorNav3: 8 VectorNav
 SG_ VectorNav_PosLlaL : 0|64@1+ (1,0) [0|0] "deg" Vector__XXX

BO_ 534 VectorNav4: 8 VectorNav
 SG_ VectorNav_PosLlaO : 0|64@1+ (1,0) [0|0] "deg" Vector__XXX

BO_ 535 VectorNav5: 8 VectorNav
 SG_ VectorNav_PosLlaA : 0|64@1+ (1,0) [0|0] "m" Vector__XXX

BO_ 536 VectorNav6: 8 VectorNav
 SG_ VectorNav_VelBodyX : 0|32@1+ (1,0) [0|0] "m/s" Vector__XXX
 SG_ VectorNav_VelBodyY : 32|32@1+ (1,0) [0|0] "m/s" Vector__XXX

BO_ 537 VectorNav7: 8 VectorNav
 SG_ VectorNav_VelBodyZ : 0|32@1+ (1,0) [0|0] "m/s" Vector__XXX
 SG_ VectorNav_YprY : 32|32@1+ (1,0) [0|0] "deg" Vector__XXX

BO_ 538 VectorNav8: 8 VectorNav
 SG_ VectorNav_YprP : 0|32@1+ (1,0) [0|0] "deg" Vector__XXX
 SG_ VectorNav_YprR : 32|32@1+ (1,0) [0|0] "deg" Vector__XXX

CM_ BU_ C70 "Bosch C70 Data Logger";
CM_ BU_ VC "Vehicle Controller";
CM_ BU_ BMS "Battery Management System";
CM_ BU_ CHG "Elcon HK-J Charger";
CM_ BU_ DASH "Dashboard Display";
CM_ BU_ SSDB "SSDB";
CM_ BU_ MCAN "MCAN";
CM_ BU_ OA "Outboard accelerometer";
CM_ SG_ 601 BMS_Overview_Drains "Number of cells currently draining";
CM_ BO_ 1790 "Wheel speeds, relayed by C70";
CM_ BO_ 1791 "Brake Pressures, relayed by C70";
BA_DEF_ SG_  "SystemSignalLongSymbol" STRING ;
BA_DEF_DEF_  "SystemSignalLongSymbol" "";
BA_ "SystemSignalLongSymbol" SG_ 469 D1_HV_Input_Current_Sensor_Valid "D1_HV_Input_Current_Sensor_Validity";
BA_ "SystemSignalLongSymbol" SG_ 700 BMS_FaultVector_SLAVE_COMM_DRAIN "BMS_FaultVector_SLAVE_COMM_DRAIN_REQUEST";
BA_ "SystemSignalLongSymbol" SG_ 700 BMS_FaultVector_CURRENT_SENSOR_C "BMS_FaultVector_CURRENT_SENSOR_COMM";
BA_ "SystemSignalLongSymbol" SG_ 700 BMS_FaultVector_CELL_VOLTAGE_IRR "BMS_FaultVector_CELL_VOLTAGE_IRRATIONAL";
BA_ "SystemSignalLongSymbol" SG_ 700 BMS_FaultVector_CELL_VOLTAGE_DIF "BMS_FaultVector_CELL_VOLTAGE_DIFF";
BA_ "SystemSignalLongSymbol" SG_ 700 BMS_FaultVector_TEMPERATURE_IRRA "BMS_FaultVector_TEMPERATURE_IRRATIONAL";
BA_ "SystemSignalLongSymbol" SG_ 701 BMS_FaultAlert_cell_comm_slave_b "BMS_FaultAlert_cell_comm_slave_board_num";
BA_ "SystemSignalLongSymbol" SG_ 701 BMS_FaultAlert_temp_comm_slave_b "BMS_FaultAlert_temp_comm_slave_board_num";
BA_ "SystemSignalLongSymbol" SG_ 701 BMS_FaultAlert_drain_comm_slave_ "BMS_FaultAlert_drain_comm_slave_board_num";
BA_ "SystemSignalLongSymbol" SG_ 701 BMS_FaultAlert_irrational_voltag "BMS_FaultAlert_irrational_voltage";
BA_ "SystemSignalLongSymbol" SG_ 701 BMS_FaultAlert_lowest_cell_volta "BMS_FaultAlert_lowest_cell_voltage";
BA_ "SystemSignalLongSymbol" SG_ 701 BMS_FaultAlert_irrational_temper "BMS_FaultAlert_irrational_temperature";
VAL_ 301 VC_Status_VehicleState 0 "VehicleState_NOT_READY" 1 "VehicleState_INVERTERS_POWERED" 2 "VehicleState_PRECHARGING" 3 "VehicleState_WAIT" 4 "VehicleState_STANDBY" 5 "VehicleState_RTD" 6 "VehicleState_SHUTDOWN";
VAL_ 315 VC_HardFaultIndicator_task 0 "unknown" 1 "task_100Hz" ;
VAL_ 600 BMS_Status_ChargeState 0 "ChargeState_DISCONNECTED" 1 "ChargeState_CONNECTED_CHARGING" 2 "ChargeState_CONNECTED_BALANCING" 3 "ChargeState_CONNECTED_BALANCE_SENSING" 4 "ChargeState_CONNECTED_COMPLETE" 5 "ChargeState_CONNECTED_FAULTED";
VAL_ 701 BMS_FaultAlert_code 0 "FaultCode_SLAVE_COMM_CELLS" 1 "FaultCode_SLAVE_COMM_TEMPS" 2 "FaultCode_SLAVE_COMM_DRAIN_REQUEST" 3 "FaultCode_CURRENT_SENSOR_COMM" 4 "FaultCode_OVER_CURRENT" 5 "FaultCode_CELL_VOLTAGE_IRRATIONAL" 6 "FaultCode_CELL_VOLTAGE_DIFF" 7 "Faultcode_OUT_OF_JUICE" 8 "FaultCode_TEMPERATURE_IRRATIONAL" 9 "FaultCode_OVER_TEMP" 10 "FaultCode_DRAIN_FAILURE" ;
VAL_ 950 BMS_HardFaultIndicator_task 0 "unknown" 1 "task_1Hz" 2 "task_10Hz" 3 "task_1kHz" 4 "can_rx_task" ;
VAL_ 901 BMS_LimpMode_VoltageLimpLevel 0 "LimpModeLevel_NO_LIMP" 1 "LimpModeLevel_LEVEL_1" 2 "LimpModeLevel_LEVEL_2" 3 "LimpModeLevel_LEVEL_3" ;
VAL_ 901 BMS_LimpMode_TempLimpLevel 0 "LimpModeLevel_NO_LIMP" 1 "LimpModeLevel_LEVEL_1" 2 "LimpModeLevel_LEVEL_2" 3 "LimpModeLevel_LEVEL_3" ;

VAL_ 311 VC_RR_Status 5 "InvState_PAIRED_HARD" 4 "InvState_PAIRED_SOFT" 3 "InvState_LOST" 2 "InvState_HARD_FAULT" 1 "InvState_SOFT_FAULT" 0 "InvState_NORMAL" ;
VAL_ 311 VC_RL_Status 5 "InvState_PAIRED_HARD" 4 "InvState_PAIRED_SOFT" 3 "InvState_LOST" 2 "InvState_HARD_FAULT" 1 "InvState_SOFT_FAULT" 0 "InvState_NORMAL" ;
VAL_ 311 VC_FR_Status 5 "InvState_PAIRED_HARD" 4 "InvState_PAIRED_SOFT" 3 "InvState_LOST" 2 "InvState_HARD_FAULT" 1 "InvState_SOFT_FAULT" 0 "InvState_NORMAL" ;
VAL_ 311 VC_FL_Status 5 "InvState_PAIRED_HARD" 4 "InvState_PAIRED_SOFT" 3 "InvState_LOST" 2 "InvState_HARD_FAULT" 1 "InvState_SOFT_FAULT" 0 "InvState_NORMAL" ;

SIG_VALTYPE_ 505 VectorNav_VelBodyX : 1;
SIG_VALTYPE_ 505 VectorNav_VelBodyY : 1;

SIG_VALTYPE_ 530 VectorNav_AccelX : 1;
SIG_VALTYPE_ 530 VectorNav_AccelY : 1;
SIG_VALTYPE_ 531 VectorNav_AccelZ : 1;
SIG_VALTYPE_ 531 VectorNav_AngularRateX : 1;
SIG_VALTYPE_ 532 VectorNav_AngularRateY : 1;
SIG_VALTYPE_ 532 VectorNav_AngularRateZ : 1;
SIG_VALTYPE_ 533 VectorNav_PosLlaL : 2;
SIG_VALTYPE_ 534 VectorNav_PosLlaO : 2;
SIG_VALTYPE_ 535 VectorNav_PosLlaA : 2;
SIG_VALTYPE_ 536 VectorNav_VelBodyX : 1;
SIG_VALTYPE_ 536 VectorNav_VelBodyY : 1;
SIG_VALTYPE_ 537 VectorNav_VelBodyZ : 1;
SIG_VALTYPE_ 537 VectorNav_YprY : 1;
SIG_VALTYPE_ 538 VectorNav_YprP : 1;
SIG_VALTYPE_ 538 VectorNav_YprR : 1;

SIG_VALTYPE_ 328 VC_debug1 : 1;
SIG_VALTYPE_ 328 VC_debug2 : 1;
SIG_VALTYPE_ 329 VC_YawRateProportional : 1;
SIG_VALTYPE_ 329 VC_YawRateIntegral : 1;
SIG_VALTYPE_ 330 VC_YawRateFeedForward : 1;
SIG_VALTYPE_ 331 VC_CodegenRR : 1;
SIG_VALTYPE_ 331 VC_CodegenRL : 1;
SIG_VALTYPE_ 332 VC_CodegenFR : 1;
SIG_VALTYPE_ 332 VC_CodegenFL : 1;
